VERSION "PrimaryActuatorCAN"

NS_ :

BS_:

BU_: ACM CGM EPAS_P ESP IBM OCS RCM SAS TestTool VDM Vector_XXX

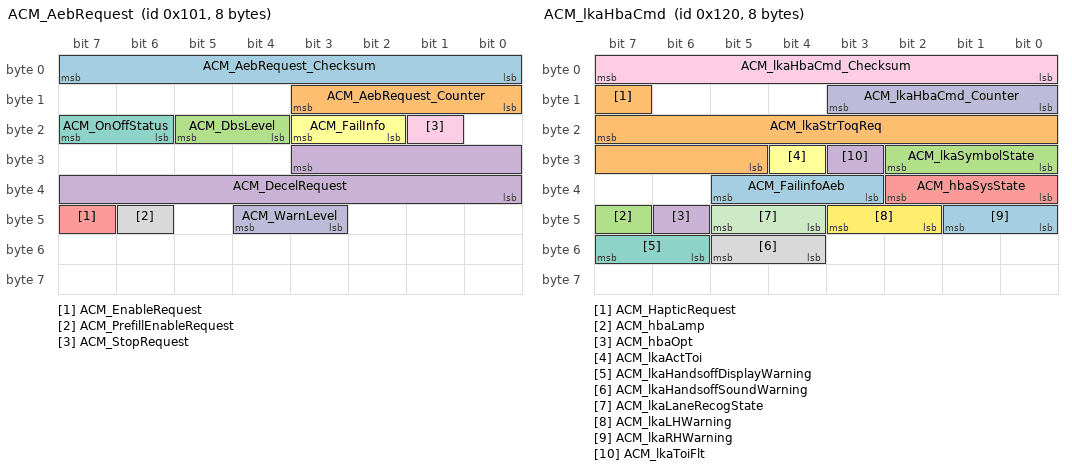
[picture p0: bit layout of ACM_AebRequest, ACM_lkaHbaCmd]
BO_ 257 ACM_AebRequest: 8 ACM
 SG_ ACM_AebRequest_Checksum : 7|8@0+ (1,0) [0|255] ""  ESP,VDM
 SG_ ACM_AebRequest_Counter : 11|4@0+ (1,0) [0|15] ""  ESP,VDM
 SG_ ACM_DbsLevel : 21|2@0+ (1,0) [0|3] ""  ESP,VDM
 SG_ ACM_DecelRequest : 27|12@0+ (0.004885,0) [0|15.998375] "m/s^2"  ESP,VDM
 SG_ ACM_EnableRequest : 47|1@0+ (1,0) [0|1] ""  ESP,VDM
 SG_ ACM_FailInfo : 19|2@0+ (1,0) [0|3] ""  ESP,VDM
 SG_ ACM_OnOffStatus : 23|2@0+ (1,0) [0|3] ""  ESP,VDM
 SG_ ACM_PrefillEnableRequest : 46|1@0+ (1,0) [0|1] ""  ESP,VDM
 SG_ ACM_StopRequest : 17|1@0+ (1,0) [0|1] ""  ESP,VDM
 SG_ ACM_WarnLevel : 44|2@0+ (1,0) [0|3] ""  ESP,VDM

BO_ 288 ACM_lkaHbaCmd: 8 ACM
 SG_ ACM_FailinfoAeb : 37|3@0+ (1,0) [0|7] ""  EPAS_P
 SG_ ACM_HapticRequest : 15|1@0+ (1,0) [0|1] ""  EPAS_P
 SG_ ACM_hbaLamp : 47|1@0+ (1,0) [0|1] ""  EPAS_P
 SG_ ACM_hbaOpt : 46|1@0+ (1,0) [0|1] ""  EPAS_P
 SG_ ACM_hbaSysState : 34|3@0+ (1,0) [0|7] ""  EPAS_P
 SG_ ACM_lkaActToi : 28|1@0+ (1,0) [0|1] ""  EPAS_P
 SG_ ACM_lkaHandsoffDisplayWarning : 55|2@0+ (1,0) [0|3] ""  EPAS_P
 SG_ ACM_lkaHandsoffSoundWarning : 53|2@0+ (1,0) [0|3] ""  EPAS_P
 SG_ ACM_lkaHbaCmd_Checksum : 7|8@0+ (1,0) [0|0] ""  EPAS_P
 SG_ ACM_lkaHbaCmd_Counter : 11|4@0+ (1,0) [0|0] ""  EPAS_P
 SG_ ACM_lkaLaneRecogState : 45|2@0+ (1,0) [0|3] ""  EPAS_P
 SG_ ACM_lkaLHWarning : 43|2@0+ (1,0) [0|3] ""  EPAS_P
 SG_ ACM_lkaRHWarning : 41|2@0+ (1,0) [0|3] ""  EPAS_P
 SG_ ACM_lkaStrToqReq : 23|11@0+ (0.0078125,-8) [-8|7.9921875] "Nm"  EPAS_P
 SG_ ACM_lkaSymbolState : 26|3@0+ (1,0) [0|7] ""  EPAS_P
 SG_ ACM_lkaToiFlt : 27|1@0+ (1,0) [0|1] ""  EPAS_P

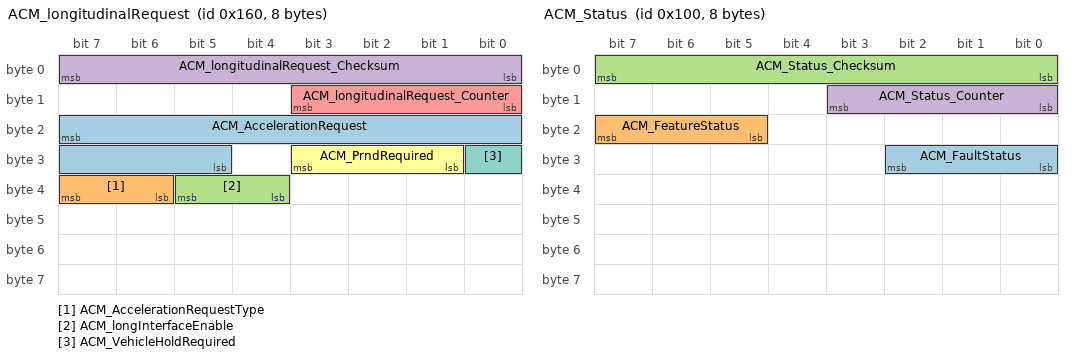
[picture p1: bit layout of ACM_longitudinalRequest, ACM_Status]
BO_ 352 ACM_longitudinalRequest: 8 ACM
 SG_ ACM_AccelerationRequest : 23|11@0+ (0.01,-10.24) [-10.24|10.23] "m/s^2"  VDM
 SG_ ACM_AccelerationRequestType : 39|2@0+ (1,0) [0|3] ""  VDM
 SG_ ACM_longInterfaceEnable : 37|2@0+ (1,0) [0|3] ""  VDM
 SG_ ACM_longitudinalRequest_Checksum : 7|8@0+ (1,0) [0|255] "-"  VDM
 SG_ ACM_longitudinalRequest_Counter : 11|4@0+ (1,0) [0|15] "-"  VDM
 SG_ ACM_PrndRequired : 27|3@0+ (1,0) [0|7] ""  VDM
 SG_ ACM_VehicleHoldRequired : 24|1@0+ (1,0) [0|1] ""  VDM

BO_ 256 ACM_Status: 8 ACM
 SG_ ACM_FaultStatus : 26|3@0+ (1,0) [0|7] ""  EPAS_P,VDM
 SG_ ACM_FeatureStatus : 23|3@0+ (1,0) [0|7] ""  EPAS_P,VDM
 SG_ ACM_Status_Checksum : 7|8@0+ (1,0) [0|255] "-"  EPAS_P,VDM
 SG_ ACM_Status_Counter : 11|4@0+ (1,0) [0|15] "-"  EPAS_P,VDM

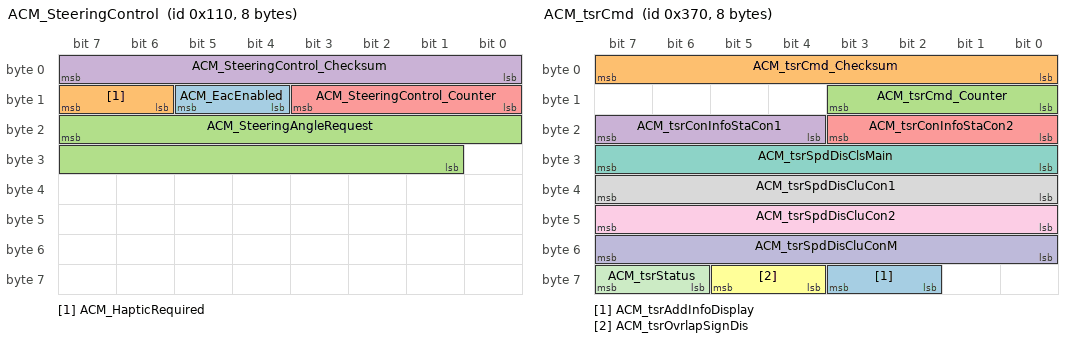
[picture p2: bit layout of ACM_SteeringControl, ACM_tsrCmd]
BO_ 272 ACM_SteeringControl: 8 ACM
 SG_ ACM_EacEnabled : 13|2@0+ (1,0) [0|3] ""  EPAS_P
 SG_ ACM_HapticRequired : 15|2@0+ (1,0) [0|3] ""  EPAS_P
 SG_ ACM_SteeringAngleRequest : 23|15@0+ (0.1,-1638.4) [-1638.4|1638.3] "deg"  EPAS_P
 SG_ ACM_SteeringControl_Checksum : 7|8@0+ (1,0) [0|0] ""  EPAS_P
 SG_ ACM_SteeringControl_Counter : 11|4@0+ (1,0) [0|0] ""  EPAS_P

BO_ 880 ACM_tsrCmd: 8 ACM
 SG_ ACM_tsrAddInfoDisplay : 59|2@0+ (1,0) [0|3] ""  Vector_XXX
 SG_ ACM_tsrCmd_Checksum : 7|8@0+ (1,0) [0|0] ""  Vector_XXX
 SG_ ACM_tsrCmd_Counter : 11|4@0+ (1,0) [0|15] ""  Vector_XXX
 SG_ ACM_tsrConInfoStaCon1 : 23|4@0+ (1,0) [0|15] ""  Vector_XXX
 SG_ ACM_tsrConInfoStaCon2 : 19|4@0+ (1,0) [0|15] ""  Vector_XXX
 SG_ ACM_tsrOvrlapSignDis : 61|2@0+ (1,0) [0|3] ""  Vector_XXX
 SG_ ACM_tsrSpdDisClsMain : 31|8@0+ (1,0) [0|255] ""  Vector_XXX
 SG_ ACM_tsrSpdDisCluCon1 : 39|8@0+ (1,0) [0|255] ""  Vector_XXX
 SG_ ACM_tsrSpdDisCluCon2 : 47|8@0+ (1,0) [0|255] ""  Vector_XXX
 SG_ ACM_tsrSpdDisCluConM : 55|8@0+ (1,0) [0|255] ""  Vector_XXX
 SG_ ACM_tsrStatus : 63|2@0+ (1,0) [0|3] ""  Vector_XXX

BO_ 789 BCM_Status: 2 VDM
 SG_ BCM_AmbientAirTemperature : 15|8@0- (1,0) [-60|100] "degC"  ESP

BO_ 1800 Diag_PhysReq_ACM_PrimaryActuator: 8 TestTool

BO_ 1843 Diag_PhysReq_EPAS_P_PrimaryActua: 8 TestTool

BO_ 1845 Diag_PhysReq_ESP_PrimaryActuator: 8 TestTool

BO_ 1846 Diag_PhysReq_IBM_PrimaryActuator: 8 TestTool

BO_ 1844 Diag_PhysReq_RCM_PrimaryActuator: 8 TestTool

BO_ 1864 Diag_PhysResp_ACM_PrimaryActuato: 8 ACM

BO_ 1907 Diag_PhysResp_EPAS_P_PrimaryActu: 8 EPAS_P

BO_ 1909 Diag_PhysResp_ESP_PrimaryActuato: 8 ESP

BO_ 1910 Diag_PhysResp_IBM_PrimaryActuato: 8 IBM

BO_ 1908 Diag_PhysResp_RCM_PrimaryActuato: 8 RCM

BO_ 1328 Dummy_ACM_PrimaryActuatorCAN: 1 ACM
 SG_ Dummy_ACM_PrimaryActuatorCAN : 7|8@0+ (1,0) [0|255] ""  TestTool

BO_ 1329 Dummy_CGM_PrimaryActuatorCAN: 1 CGM
 SG_ Dummy_CGM_PrimaryActuatorCAN : 7|8@0+ (1,0) [0|255] ""  TestTool

BO_ 1330 Dummy_VDM_PrimaryActuatorCAN: 1 VDM
 SG_ Dummy_VDM_PrimaryActuatorCAN : 7|8@0+ (1,0) [0|255] ""  TestTool

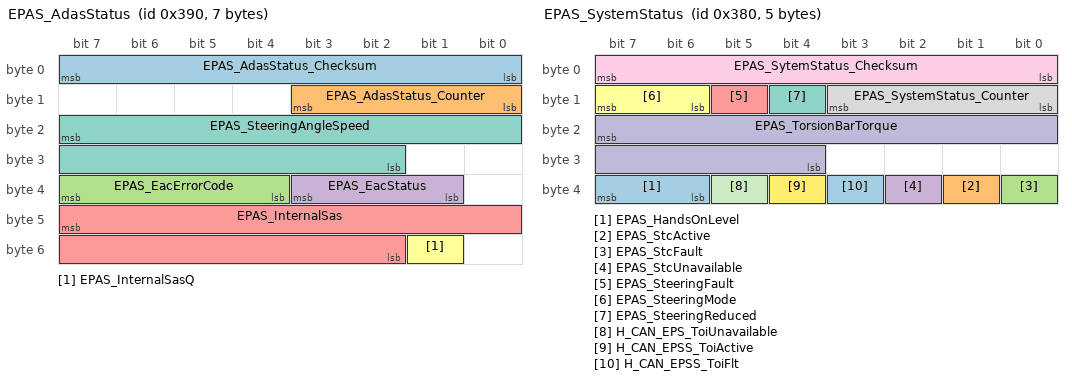
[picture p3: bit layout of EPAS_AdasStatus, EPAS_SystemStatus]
BO_ 912 EPAS_AdasStatus: 7 EPAS_P
 SG_ EPAS_AdasStatus_Checksum : 7|8@0+ (1,0) [0|0] ""  ACM,VDM
 SG_ EPAS_AdasStatus_Counter : 11|4@0+ (1,0) [0|15] ""  ACM,VDM
 SG_ EPAS_EacErrorCode : 39|4@0+ (1,0) [0|15] ""  ACM,VDM
 SG_ EPAS_EacStatus : 35|3@0+ (1,0) [0|7] ""  ACM,VDM
 SG_ EPAS_InternalSas : 47|14@0+ (0.1,-819.2) [-819.2|819] "deg"  ACM,VDM
 SG_ EPAS_InternalSasQ : 49|1@0+ (1,0) [0|1] ""  ACM,VDM
 SG_ EPAS_SteeringAngleSpeed : 23|14@0+ (0.1,-819) [-819|819.3] "deg/s"  ACM,VDM

BO_ 896 EPAS_SystemStatus: 5 EPAS_P
 SG_ EPAS_HandsOnLevel : 39|2@0+ (1,0) [0|3] ""  ACM,VDM
 SG_ EPAS_StcActive : 33|1@0+ (1,0) [0|1] ""  ACM,VDM
 SG_ EPAS_StcFault : 32|1@0+ (1,0) [0|1] ""  ACM,VDM
 SG_ EPAS_StcUnavailable : 34|1@0+ (1,0) [0|1] ""  ACM,VDM
 SG_ EPAS_SteeringFault : 13|1@0+ (1,0) [0|1] ""  ACM,VDM
 SG_ EPAS_SteeringMode : 15|2@0+ (1,0) [0|3] ""  ACM,VDM
 SG_ EPAS_SteeringReduced : 12|1@0+ (1,0) [0|1] ""  ACM,VDM
 SG_ EPAS_SystemStatus_Counter : 11|4@0+ (1,0) [0|15] ""  ACM,VDM
 SG_ EPAS_SytemStatus_Checksum : 7|8@0+ (1,0) [0|255] ""  ACM,VDM
 SG_ EPAS_TorsionBarTorque : 23|12@0+ (0.01,-20.5) [-20.49|20.43] ""  ACM,VDM
 SG_ H_CAN_EPS_ToiUnavailable : 37|1@0+ (1,0) [0|1] ""  ACM,VDM
 SG_ H_CAN_EPSS_ToiActive : 36|1@0+ (1,0) [0|1] ""  ACM,VDM
 SG_ H_CAN_EPSS_ToiFlt : 35|1@0+ (1,0) [0|1] ""  ACM,VDM

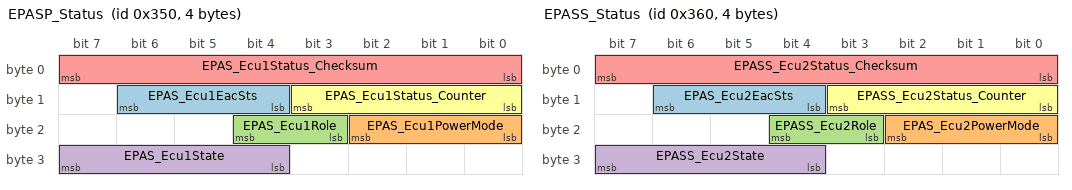
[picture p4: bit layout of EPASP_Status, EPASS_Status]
BO_ 848 EPASP_Status: 4 EPAS_P
 SG_ EPAS_Ecu1EacSts : 14|3@0+ (1,0) [0|7] ""  ACM,VDM
 SG_ EPAS_Ecu1PowerMode : 18|3@0+ (1,0) [0|7] ""  ACM,VDM
 SG_ EPAS_Ecu1Role : 20|2@0+ (1,0) [0|3] ""  ACM,VDM
 SG_ EPAS_Ecu1State : 31|4@0+ (1,0) [0|15] ""  ACM,VDM
 SG_ EPAS_Ecu1Status_Checksum : 7|8@0+ (1,0) [0|255] ""  ACM,VDM
 SG_ EPAS_Ecu1Status_Counter : 11|4@0+ (1,0) [0|15] ""  ACM,VDM

BO_ 864 EPASS_Status: 4 VDM
 SG_ EPAS_Ecu2EacSts : 14|3@0+ (1,0) [0|7] ""  ACM,EPAS_P
 SG_ EPAS_Ecu2PowerMode : 18|3@0+ (1,0) [0|7] ""  ACM,EPAS_P
 SG_ EPASS_Ecu2Role : 20|2@0+ (1,0) [0|3] ""  ACM,EPAS_P
 SG_ EPASS_Ecu2State : 31|4@0+ (1,0) [0|15] ""  ACM,EPAS_P
 SG_ EPASS_Ecu2Status_Checksum : 7|8@0+ (1,0) [0|255] ""  ACM,EPAS_P
 SG_ EPASS_Ecu2Status_Counter : 11|4@0+ (1,0) [0|15] ""  ACM,EPAS_P

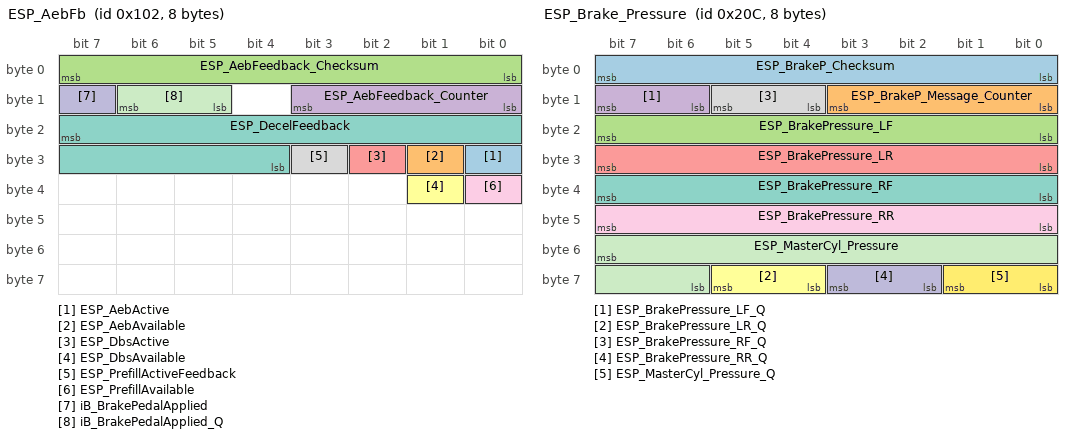
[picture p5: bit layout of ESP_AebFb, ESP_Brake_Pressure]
BO_ 258 ESP_AebFb: 8 ESP
 SG_ ESP_AebActive : 24|1@0+ (1,0) [0|1] ""  ACM
 SG_ ESP_AebAvailable : 25|1@0+ (1,0) [0|1] ""  ACM
 SG_ ESP_AebFeedback_Checksum : 7|8@0+ (1,0) [0|255] ""  ACM
 SG_ ESP_AebFeedback_Counter : 11|4@0+ (1,0) [0|15] ""  ACM
 SG_ ESP_DbsActive : 26|1@0+ (1,0) [0|1] ""  ACM
 SG_ ESP_DbsAvailable : 33|1@0+ (1,0) [0|1] ""  ACM
 SG_ ESP_DecelFeedback : 23|12@0+ (0.004885,-16) [-16|3.99919] "m/s^2"  ACM
 SG_ ESP_PrefillActiveFeedback : 27|1@0+ (1,0) [0|1] ""  ACM
 SG_ ESP_PrefillAvailable : 32|1@0+ (1,0) [0|1] ""  ACM
 SG_ iB_BrakePedalApplied : 15|1@0+ (1,0) [0|1] ""  ACM
 SG_ iB_BrakePedalApplied_Q : 14|2@0+ (1,0) [0|3] ""  ACM

BO_ 524 ESP_Brake_Pressure: 8 ESP
 SG_ ESP_BrakeP_Checksum : 7|8@0+ (1,0) [0|255] ""  ACM,RCM,VDM
 SG_ ESP_BrakeP_Message_Counter : 11|4@0+ (1,0) [0|15] ""  ACM,RCM,VDM
 SG_ ESP_BrakePressure_LF : 23|8@0+ (1,0) [0|255] "bar"  ACM,RCM,VDM
 SG_ ESP_BrakePressure_LF_Q : 15|2@0+ (1,0) [0|3] ""  ACM,RCM,VDM
 SG_ ESP_BrakePressure_LR : 31|8@0+ (1,0) [0|255] "bar"  ACM,RCM,VDM
 SG_ ESP_BrakePressure_LR_Q : 61|2@0+ (1,0) [0|3] ""  ACM,RCM,VDM
 SG_ ESP_BrakePressure_RF : 39|8@0+ (1,0) [0|255] "bar"  ACM,RCM,VDM
 SG_ ESP_BrakePressure_RF_Q : 13|2@0+ (1,0) [0|3] ""  ACM,RCM,VDM
 SG_ ESP_BrakePressure_RR : 47|8@0+ (1,0) [0|255] "bar"  ACM,RCM,VDM
 SG_ ESP_BrakePressure_RR_Q : 59|2@0+ (1,0) [0|3] ""  ACM,RCM,VDM
 SG_ ESP_MasterCyl_Pressure : 55|10@0+ (0.25,0) [0|255] "bar"  ACM,RCM,VDM
 SG_ ESP_MasterCyl_Pressure_Q : 57|2@0+ (1,0) [0|3] ""  ACM,RCM,VDM

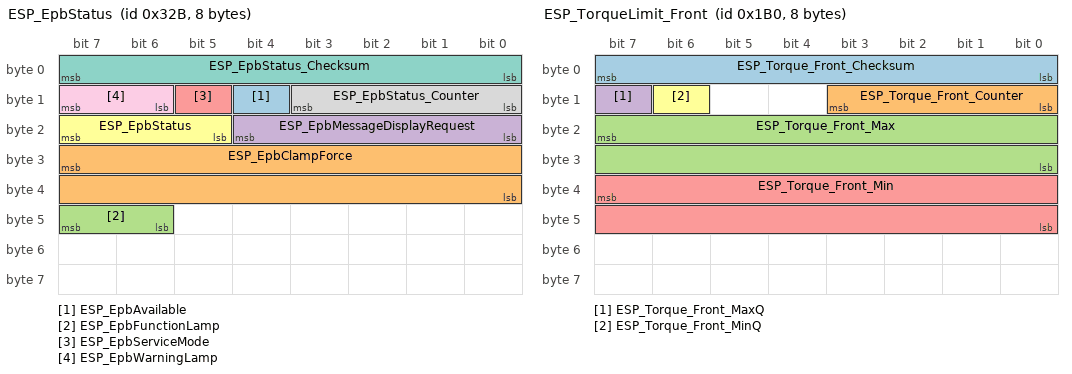
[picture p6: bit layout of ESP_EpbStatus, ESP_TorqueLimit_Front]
BO_ 811 ESP_EpbStatus: 8 ESP
 SG_ ESP_EpbAvailable : 12|1@0+ (1,0) [0|1] ""  ACM,VDM
 SG_ ESP_EpbClampForce : 31|16@0+ (1,0) [0|65534] "N"  ACM,VDM
 SG_ ESP_EpbFunctionLamp : 47|2@0+ (1,0) [0|3] ""  ACM,VDM
 SG_ ESP_EpbMessageDisplayRequest : 20|5@0+ (1,0) [0|30] ""  ACM,VDM
 SG_ ESP_EpbServiceMode : 13|1@0+ (1,0) [0|1] ""  ACM,VDM
 SG_ ESP_EpbStatus : 23|3@0+ (1,0) [0|7] ""  ACM,VDM
 SG_ ESP_EpbStatus_Checksum : 7|8@0+ (1,0) [0|255] ""  ACM,VDM
 SG_ ESP_EpbStatus_Counter : 11|4@0+ (1,0) [0|15] ""  ACM,VDM
 SG_ ESP_EpbWarningLamp : 15|2@0+ (1,0) [0|3] ""  ACM,VDM

BO_ 520 ESP_Status: 8 ESP
 SG_ ESP_Abs_Active : 23|1@0+ (1,0) [0|1] ""  ACM,CGM,EPAS_P,RCM,VDM
 SG_ ESP_Abs_OffRoad_Mode : 16|1@0+ (1,0) [0|1] ""  ACM,CGM,EPAS_P,RCM,VDM
 SG_ ESP_BrakeLightActive : 13|1@0+ (1,0) [0|1] ""  ACM,CGM,EPAS_P,RCM,VDM
 SG_ ESP_BrakeLightActive_Q : 12|1@0+ (1,0) [0|1] ""  ACM,CGM,EPAS_P,RCM,VDM
 SG_ ESP_BrkTrq : 38|15@0+ (2,-65534) [-65534|0] "Nm"  ACM,CGM,EPAS_P,RCM,VDM
 SG_ ESP_Dtc_Active : 26|1@0+ (1,0) [0|1] "Enum"  ACM,CGM,EPAS_P,RCM,VDM
 SG_ ESP_Esp_Active : 21|1@0+ (1,0) [0|1] ""  ACM,CGM,EPAS_P,RCM,VDM
 SG_ ESP_FaultLamp_ABS : 20|1@0+ (1,0) [0|1] ""  ACM,CGM,EPAS_P,RCM,VDM
 SG_ ESP_FaultLamp_EBD : 18|1@0+ (1,0) [0|1] ""  ACM,CGM,EPAS_P,RCM,VDM
 SG_ ESP_FaultLamp_VDC : 19|1@0+ (1,0) [0|1] ""  ACM,CGM,EPAS_P,RCM,VDM
 SG_ ESP_Hba_Active : 31|1@0+ (1,0) [0|1] ""  ACM,CGM,EPAS_P,RCM,VDM
 SG_ ESP_Hhc_Active : 14|1@0+ (1,0) [0|1] ""  ACM,CGM,EPAS_P,RCM,VDM
 SG_ ESP_Hhc_Available : 15|1@0+ (1,0) [0|1] ""  ACM,CGM,EPAS_P,RCM,VDM
 SG_ ESP_Lfc_Active : 39|1@0+ (1,0) [0|1] ""  ACM,CGM,EPAS_P,RCM,VDM
 SG_ ESP_Lfc_Available : 30|1@0+ (1,0) [0|1] ""  ACM,CGM,EPAS_P,RCM,VDM
 SG_ ESP_Partial_Mode : 25|2@0+ (1,0) [0|3] ""  ACM,CGM,EPAS_P,RCM,VDM
 SG_ ESP_Status_Checksum : 7|8@0+ (1,0) [0|255] ""  ACM,CGM,EPAS_P,RCM,VDM
 SG_ ESP_Status_Counter : 11|4@0+ (1,0) [0|15] ""  ACM,CGM,EPAS_P,RCM,VDM
 SG_ ESP_Tsm_Active : 17|1@0+ (1,0) [0|1] ""  ACM,CGM,EPAS_P,RCM,VDM
 SG_ ESP_Vehicle_Speed : 55|16@0+ (0.01,0) [0|400] "kph"  ACM,CGM,EPAS_P,RCM,VDM
 SG_ ESP_Vehicle_Speed_Q : 28|2@0+ (1,0) [0|3] ""  ACM,CGM,EPAS_P,RCM,VDM

BO_ 432 ESP_TorqueLimit_Front: 8 ESP
 SG_ ESP_Torque_Front_Checksum : 7|8@0+ (1,0) [0|255] ""  VDM
 SG_ ESP_Torque_Front_Counter : 11|4@0+ (1,0) [0|15] ""  VDM
 SG_ ESP_Torque_Front_Max : 23|16@0+ (0.5,-16384) [-16384|16383] "Nm"  VDM
 SG_ ESP_Torque_Front_MaxQ : 15|1@0+ (1,0) [0|1] ""  VDM
 SG_ ESP_Torque_Front_Min : 39|16@0+ (0.5,-16384) [-16384|16383] "Nm"  VDM
 SG_ ESP_Torque_Front_MinQ : 14|1@0+ (1,0) [0|1] ""  VDM

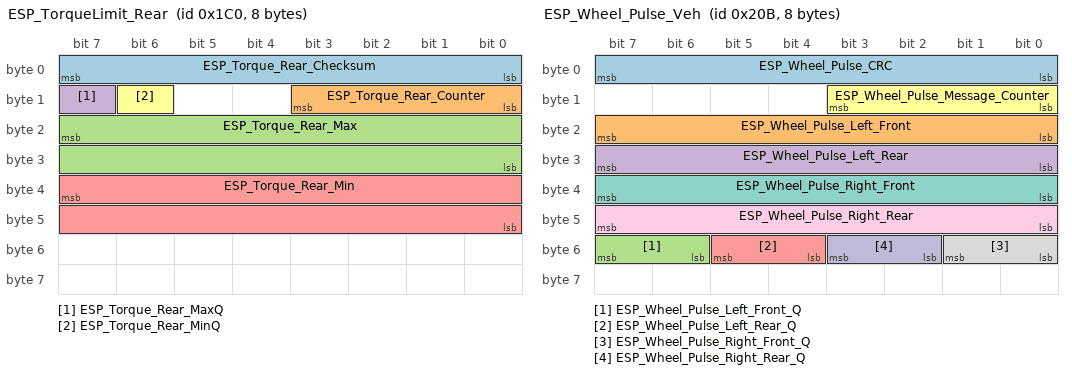
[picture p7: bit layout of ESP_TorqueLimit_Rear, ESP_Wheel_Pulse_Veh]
BO_ 448 ESP_TorqueLimit_Rear: 8 ESP
 SG_ ESP_Torque_Rear_Checksum : 7|8@0+ (1,0) [0|255] ""  VDM
 SG_ ESP_Torque_Rear_Counter : 11|4@0+ (1,0) [0|15] ""  VDM
 SG_ ESP_Torque_Rear_Max : 23|16@0+ (0.5,-16384) [-16384|16383] "Nm"  VDM
 SG_ ESP_Torque_Rear_MaxQ : 15|1@0+ (1,0) [0|1] ""  VDM
 SG_ ESP_Torque_Rear_Min : 39|16@0+ (0.5,-16384) [-16384|16383] "Nm"  VDM
 SG_ ESP_Torque_Rear_MinQ : 14|1@0+ (1,0) [0|1] ""  VDM

BO_ 523 ESP_Wheel_Pulse_Veh: 8 ESP
 SG_ ESP_Wheel_Pulse_CRC : 7|8@0+ (1,0) [0|255] ""  ACM,VDM
 SG_ ESP_Wheel_Pulse_Left_Front : 23|8@0+ (1,0) [0|255] "Pulse"  ACM,VDM
 SG_ ESP_Wheel_Pulse_Left_Front_Q : 55|2@0+ (1,0) [0|3] ""  ACM,VDM
 SG_ ESP_Wheel_Pulse_Left_Rear : 31|8@0+ (1,0) [0|255] "Pulse"  ACM,VDM
 SG_ ESP_Wheel_Pulse_Left_Rear_Q : 53|2@0+ (1,0) [0|3] ""  ACM,VDM
 SG_ ESP_Wheel_Pulse_Message_Counter : 11|4@0+ (1,0) [0|15] ""  ACM,VDM
 SG_ ESP_Wheel_Pulse_Right_Front : 39|8@0+ (1,0) [0|255] "Pulse"  ACM,VDM
 SG_ ESP_Wheel_Pulse_Right_Front_Q : 49|2@0+ (1,0) [0|3] ""  ACM,VDM
 SG_ ESP_Wheel_Pulse_Right_Rear : 47|8@0+ (1,0) [0|255] "Pulse"  ACM,VDM
 SG_ ESP_Wheel_Pulse_Right_Rear_Q : 51|2@0+ (1,0) [0|3] ""  ACM,VDM

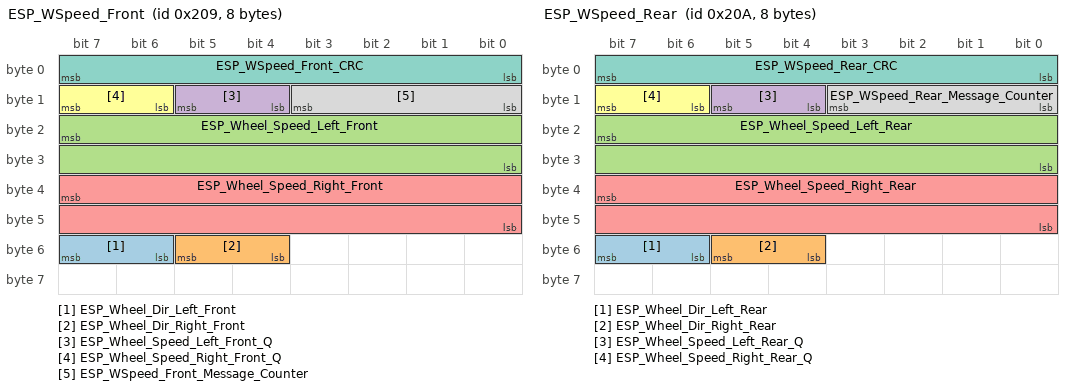
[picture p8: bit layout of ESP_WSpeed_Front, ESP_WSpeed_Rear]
BO_ 521 ESP_WSpeed_Front: 8 ESP
 SG_ ESP_Wheel_Dir_Left_Front : 55|2@0+ (1,0) [0|3] ""  ACM,VDM
 SG_ ESP_Wheel_Dir_Right_Front : 53|2@0+ (1,0) [0|3] ""  ACM,VDM
 SG_ ESP_Wheel_Speed_Left_Front : 23|16@0+ (0.01,0) [0|400] "kph"  ACM,VDM
 SG_ ESP_Wheel_Speed_Left_Front_Q : 13|2@0+ (1,0) [0|3] ""  ACM,VDM
 SG_ ESP_Wheel_Speed_Right_Front : 39|16@0+ (0.01,0) [0|400] "kph"  ACM,VDM
 SG_ ESP_Wheel_Speed_Right_Front_Q : 15|2@0+ (1,0) [0|3] ""  ACM,VDM
 SG_ ESP_WSpeed_Front_CRC : 7|8@0+ (1,0) [0|255] ""  ACM,VDM
 SG_ ESP_WSpeed_Front_Message_Counter : 11|4@0+ (1,0) [0|15] ""  ACM,VDM

BO_ 522 ESP_WSpeed_Rear: 8 ESP
 SG_ ESP_Wheel_Dir_Left_Rear : 55|2@0+ (1,0) [0|3] ""  ACM,VDM
 SG_ ESP_Wheel_Dir_Right_Rear : 53|2@0+ (1,0) [0|3] ""  ACM,VDM
 SG_ ESP_Wheel_Speed_Left_Rear : 23|16@0+ (0.01,0) [0|400] "kph"  ACM,VDM
 SG_ ESP_Wheel_Speed_Left_Rear_Q : 13|2@0+ (1,0) [0|3] ""  ACM,VDM
 SG_ ESP_Wheel_Speed_Right_Rear : 39|16@0+ (0.01,0) [0|400] "kph"  ACM,VDM
 SG_ ESP_Wheel_Speed_Right_Rear_Q : 15|2@0+ (1,0) [0|3] ""  ACM,VDM
 SG_ ESP_WSpeed_Rear_CRC : 7|8@0+ (1,0) [0|255] ""  ACM,VDM
 SG_ ESP_WSpeed_Rear_Message_Counter : 11|4@0+ (1,0) [0|15] ""  ACM,VDM

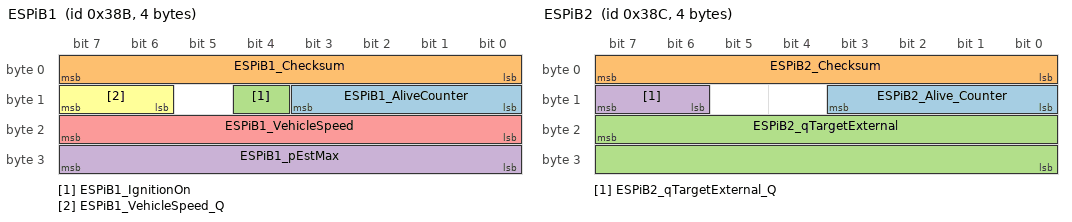
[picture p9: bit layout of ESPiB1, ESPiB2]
BO_ 907 ESPiB1: 4 ESP
 SG_ ESPiB1_AliveCounter : 11|4@0+ (1,0) [0|15] ""  IBM
 SG_ ESPiB1_Checksum : 7|8@0+ (1,0) [0|255] ""  IBM
 SG_ ESPiB1_IgnitionOn : 12|1@0+ (1,0) [0|1] ""  IBM
 SG_ ESPiB1_pEstMax : 31|8@0+ (1,0) [0|250] "bar"  IBM
 SG_ ESPiB1_VehicleSpeed : 23|8@0+ (0.4,0) [0|100] "m/s"  IBM
 SG_ ESPiB1_VehicleSpeed_Q : 15|2@0+ (1,0) [0|3] ""  IBM

BO_ 908 ESPiB2: 4 ESP
 SG_ ESPiB2_Alive_Counter : 11|4@0+ (1,0) [0|15] ""  IBM
 SG_ ESPiB2_Checksum : 7|8@0+ (1,0) [0|255] ""  IBM
 SG_ ESPiB2_qTargetExternal : 23|16@0+ (0.0078125,-252) [-252|252] "ml/s"  IBM
 SG_ ESPiB2_qTargetExternal_Q : 15|2@0+ (1,0) [0|3] ""  IBM

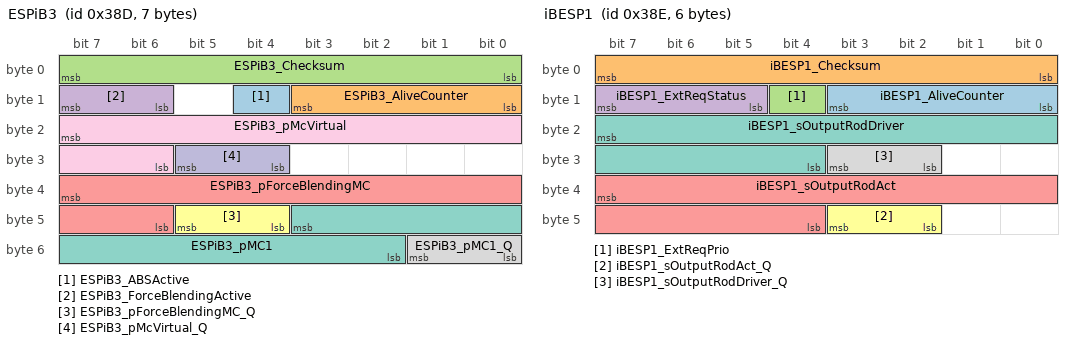
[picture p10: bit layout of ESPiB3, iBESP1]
BO_ 909 ESPiB3: 7 ESP
 SG_ ESPiB3_ABSActive : 12|1@0+ (1,0) [0|1] ""  IBM
 SG_ ESPiB3_AliveCounter : 11|4@0+ (1,0) [0|15] ""  IBM
 SG_ ESPiB3_Checksum : 7|8@0+ (1,0) [0|255] ""  IBM
 SG_ ESPiB3_ForceBlendingActive : 15|2@0+ (1,0) [0|3] ""  IBM
 SG_ ESPiB3_pForceBlendingMC : 39|10@0+ (0.25,0) [0|250] ""  IBM
 SG_ ESPiB3_pForceBlendingMC_Q : 45|2@0+ (1,0) [0|3] ""  IBM
 SG_ ESPiB3_pMC1 : 43|10@0+ (0.3,-30) [-30|276.6] "bar"  IBM
 SG_ ESPiB3_pMC1_Q : 49|2@0+ (1,0) [0|3] ""  IBM
 SG_ ESPiB3_pMcVirtual : 23|10@0+ (0.25,0) [0|250] "bar"  IBM
 SG_ ESPiB3_pMcVirtual_Q : 29|2@0+ (1,0) [0|3] ""  IBM

BO_ 910 iBESP1: 6 IBM
 SG_ iBESP1_AliveCounter : 11|4@0+ (1,0) [0|15] ""  ESP,VDM
 SG_ iBESP1_Checksum : 7|8@0+ (1,0) [0|255] ""  ESP,VDM
 SG_ iBESP1_ExtReqPrio : 12|1@0+ (1,0) [0|1] ""  ESP,VDM
 SG_ iBESP1_ExtReqStatus : 15|3@0+ (1,0) [0|7] ""  ESP,VDM
 SG_ iBESP1_sOutputRodAct : 39|12@0+ (0.015625,-5) [-5|47] "mm"  ESP,VDM
 SG_ iBESP1_sOutputRodAct_Q : 43|2@0+ (1,0) [0|3] ""  ESP,VDM
 SG_ iBESP1_sOutputRodDriver : 23|12@0+ (0.015625,-5) [-5|47] "mm"  ESP,VDM
 SG_ iBESP1_sOutputRodDriver_Q : 27|2@0+ (1,0) [0|3] ""  ESP,VDM

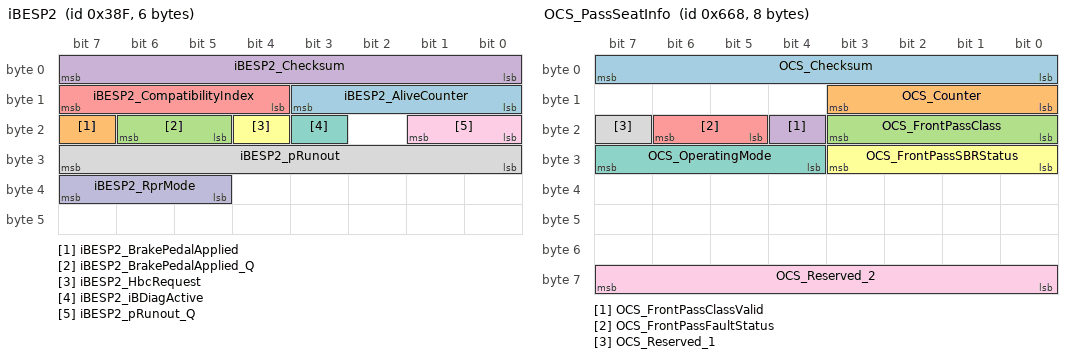
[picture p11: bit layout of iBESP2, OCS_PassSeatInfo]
BO_ 911 iBESP2: 6 IBM
 SG_ iBESP2_AliveCounter : 11|4@0+ (1,0) [0|15] ""  ACM,ESP,VDM
 SG_ iBESP2_BrakePedalApplied : 23|1@0+ (1,0) [0|1] ""  ACM,ESP,VDM
 SG_ iBESP2_BrakePedalApplied_Q : 22|2@0+ (1,0) [0|3] ""  ACM,ESP,VDM
 SG_ iBESP2_Checksum : 7|8@0+ (1,0) [0|255] ""  ACM,ESP,VDM
 SG_ iBESP2_CompatibilityIndex : 15|4@0+ (1,0) [0|15] ""  ACM,ESP,VDM
 SG_ iBESP2_HbcRequest : 20|1@0+ (1,0) [0|1] ""  ACM,ESP,VDM
 SG_ iBESP2_iBDiagActive : 19|1@0+ (1,0) [0|1] ""  ACM,ESP,VDM
 SG_ iBESP2_pRunout : 31|8@0+ (1,0) [0|250] "bar"  ACM,ESP,VDM
 SG_ iBESP2_pRunout_Q : 17|2@0+ (1,0) [0|3] ""  ACM,ESP,VDM
 SG_ iBESP2_RprMode : 39|3@0+ (1,0) [0|7] ""  ACM,ESP,VDM

BO_ 1640 OCS_PassSeatInfo: 8 OCS
 SG_ OCS_Checksum : 0|8@1+ (1,0) [0|255] "-"  RCM
 SG_ OCS_Counter : 8|4@1+ (1,0) [0|15] "-"  RCM
 SG_ OCS_FrontPassClass : 16|4@1+ (1,0) [0|15] ""  RCM
 SG_ OCS_FrontPassClassValid : 20|1@1+ (1,0) [0|1] ""  RCM
 SG_ OCS_FrontPassFaultStatus : 21|2@1+ (1,0) [0|3] ""  RCM
 SG_ OCS_FrontPassSBRStatus : 24|4@1+ (1,0) [0|15] ""  RCM
 SG_ OCS_OperatingMode : 28|4@1+ (1,0) [0|15] ""  RCM
 SG_ OCS_Reserved_1 : 23|1@1+ (1,0) [0|1] ""  RCM
 SG_ OCS_Reserved_2 : 56|8@1+ (1,0) [0|255] ""  RCM

BO_ 516 RCM_ALR_Status: 1 RCM
 SG_ RCM_ALR_Status_Signal : 0|2@1+ (1,0) [0|3] ""  OCS

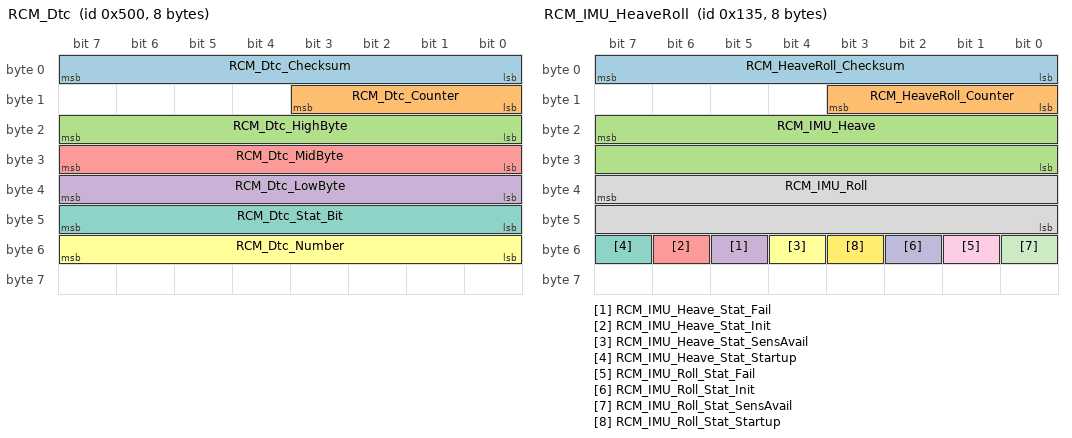
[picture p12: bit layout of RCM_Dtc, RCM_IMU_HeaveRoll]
BO_ 1280 RCM_Dtc: 8 RCM
 SG_ RCM_Dtc_Checksum : 7|8@0+ (1,0) [0|25] ""  VDM
 SG_ RCM_Dtc_Counter : 11|4@0+ (1,0) [0|15] ""  VDM
 SG_ RCM_Dtc_HighByte : 23|8@0+ (1,0) [0|255] ""  VDM
 SG_ RCM_Dtc_LowByte : 39|8@0+ (1,0) [0|255] ""  VDM
 SG_ RCM_Dtc_MidByte : 31|8@0+ (1,0) [0|255] ""  VDM
 SG_ RCM_Dtc_Number : 55|8@0+ (1,0) [0|255] ""  VDM
 SG_ RCM_Dtc_Stat_Bit : 47|8@0+ (1,0) [0|255] ""  VDM

BO_ 309 RCM_IMU_HeaveRoll: 8 RCM
 SG_ RCM_HeaveRoll_Checksum : 7|8@0+ (1,0) [0|25] ""  VDM
 SG_ RCM_HeaveRoll_Counter : 11|4@0+ (1,0) [0|15] ""  VDM
 SG_ RCM_IMU_Heave : 23|16@0+ (0.004998293,-163.784065024) [-34.32328|34.32328] "m/s2"  VDM
 SG_ RCM_IMU_Heave_Stat_Fail : 53|1@0+ (1,0) [0|1] ""  VDM
 SG_ RCM_IMU_Heave_Stat_Init : 54|1@0+ (1,0) [0|1] ""  VDM
 SG_ RCM_IMU_Heave_Stat_SensAvail : 52|1@0+ (1,0) [0|1] ""  VDM
 SG_ RCM_IMU_Heave_Stat_Startup : 55|1@0+ (1,0) [0|1] ""  VDM
 SG_ RCM_IMU_Roll : 39|16@0+ (0.0125,-409.6) [-100.0125|100.0125] "deg/sec"  VDM
 SG_ RCM_IMU_Roll_Stat_Fail : 49|1@0+ (1,0) [0|1] ""  VDM
 SG_ RCM_IMU_Roll_Stat_Init : 50|1@0+ (1,0) [0|1] ""  VDM
 SG_ RCM_IMU_Roll_Stat_SensAvail : 48|1@0+ (1,0) [0|1] ""  VDM
 SG_ RCM_IMU_Roll_Stat_Startup : 51|1@0+ (1,0) [0|1] ""  VDM

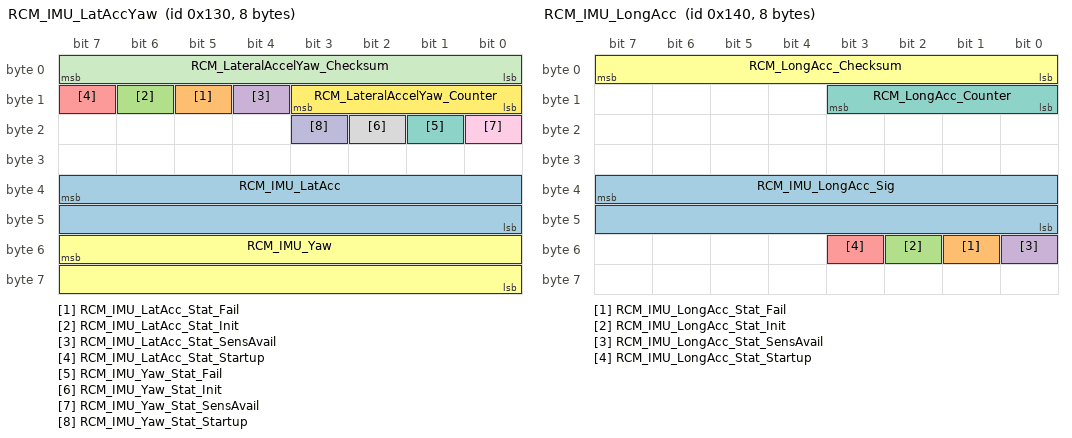
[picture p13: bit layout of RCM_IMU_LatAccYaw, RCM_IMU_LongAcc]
BO_ 304 RCM_IMU_LatAccYaw: 8 RCM
 SG_ RCM_IMU_LatAcc : 39|16@0+ (0.004998293,-163.784065024) [-40.961|40.961] "m/s2"  ACM,ESP,VDM
 SG_ RCM_IMU_LatAcc_Stat_Fail : 13|1@0+ (1,0) [0|1] ""  ACM,ESP,VDM
 SG_ RCM_IMU_LatAcc_Stat_Init : 14|1@0+ (1,0) [0|1] ""  ACM,ESP,VDM
 SG_ RCM_IMU_LatAcc_Stat_SensAvail : 12|1@0+ (1,0) [0|1] ""  ACM,ESP,VDM
 SG_ RCM_IMU_LatAcc_Stat_Startup : 15|1@0+ (1,0) [0|1] ""  ACM,ESP,VDM
 SG_ RCM_IMU_Yaw : 55|16@0+ (0.0125,-409.6) [-163.85|163.85] "deg/sec"  ACM,ESP,VDM
 SG_ RCM_IMU_Yaw_Stat_Fail : 17|1@0+ (1,0) [0|1] ""  ACM,ESP,VDM
 SG_ RCM_IMU_Yaw_Stat_Init : 18|1@0+ (1,0) [0|1] ""  ACM,ESP,VDM
 SG_ RCM_IMU_Yaw_Stat_SensAvail : 16|1@0+ (1,0) [0|1] ""  ACM,ESP,VDM
 SG_ RCM_IMU_Yaw_Stat_Startup : 19|1@0+ (1,0) [0|1] ""  ACM,ESP,VDM
 SG_ RCM_LateralAccelYaw_Checksum : 7|8@0+ (1,0) [0|25] ""  ACM,ESP,VDM
 SG_ RCM_LateralAccelYaw_Counter : 11|4@0+ (1,0) [0|15] ""  ACM,ESP,VDM

BO_ 320 RCM_IMU_LongAcc: 8 RCM
 SG_ RCM_IMU_LongAcc_Sig : 39|16@0+ (0.004998293,-163.784065024) [-40.961|40.961] "m/s2"  ACM,ESP,VDM
 SG_ RCM_IMU_LongAcc_Stat_Fail : 49|1@0+ (1,0) [0|1] ""  ACM,ESP,VDM
 SG_ RCM_IMU_LongAcc_Stat_Init : 50|1@0+ (1,0) [0|1] ""  ACM,ESP,VDM
 SG_ RCM_IMU_LongAcc_Stat_SensAvail : 48|1@0+ (1,0) [0|1] ""  ACM,ESP,VDM
 SG_ RCM_IMU_LongAcc_Stat_Startup : 51|1@0+ (1,0) [0|1] ""  ACM,ESP,VDM
 SG_ RCM_LongAcc_Checksum : 7|8@0+ (1,0) [0|25] ""  ACM,ESP,VDM
 SG_ RCM_LongAcc_Counter : 11|4@0+ (1,0) [0|15] ""  ACM,ESP,VDM

BO_ 1281 RCM_SerialIdentifier: 8 RCM
 SG_ RCM_SerialNumber : 7|64@0+ (1,0) [0|1.84467440737096E+019] ""  ESP,VDM

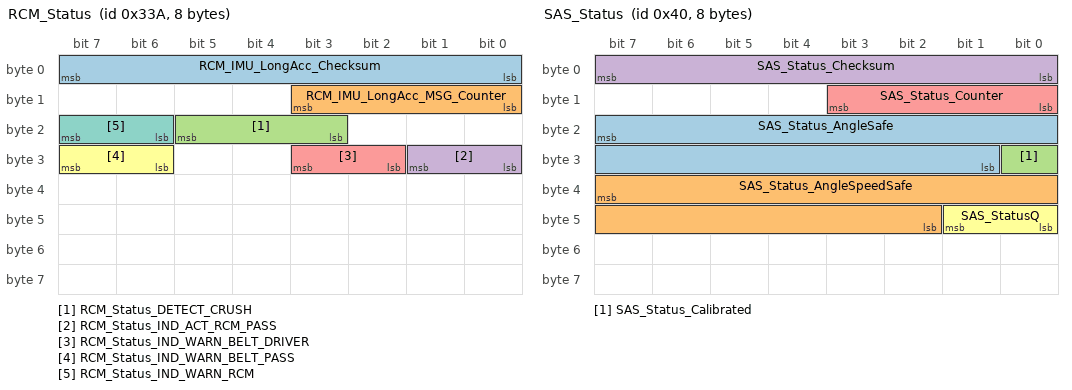
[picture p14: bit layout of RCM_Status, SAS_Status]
BO_ 826 RCM_Status: 8 RCM
 SG_ RCM_IMU_LongAcc_Checksum : 7|8@0+ (1,0) [0|25] ""  ACM,ESP,VDM
 SG_ RCM_IMU_LongAcc_MSG_Counter : 11|4@0+ (1,0) [0|15] ""  ACM,ESP,VDM
 SG_ RCM_Status_DETECT_CRUSH : 21|3@0+ (1,0) [0|7] ""  ACM,ESP,VDM
 SG_ RCM_Status_IND_ACT_RCM_PASS : 25|2@0+ (1,0) [0|3] ""  ACM,ESP,VDM
 SG_ RCM_Status_IND_WARN_BELT_DRIVER : 27|2@0+ (1,0) [0|3] ""  ACM,ESP,VDM
 SG_ RCM_Status_IND_WARN_BELT_PASS : 31|2@0+ (1,0) [0|3] ""  ACM,ESP,VDM
 SG_ RCM_Status_IND_WARN_RCM : 23|2@0+ (1,0) [0|3] ""  ACM,ESP,VDM

BO_ 64 SAS_Status: 8 SAS
 SG_ SAS_Status_AngleSafe : 23|15@0- (0.0009765625,0) [-14.5|14.5] "rad"  ACM,EPAS_P,ESP,RCM,VDM
 SG_ SAS_Status_AngleSpeedSafe : 39|14@0- (0.0078125,0) [-50|50] "rad/s"  ACM,EPAS_P,ESP,RCM,VDM
 SG_ SAS_Status_Calibrated : 24|1@0+ (1,0) [0|1] ""  ACM,EPAS_P,ESP,RCM,VDM
 SG_ SAS_Status_Checksum : 7|8@0+ (1,0) [0|255] "Unitless"  ACM,EPAS_P,ESP,RCM,VDM
 SG_ SAS_Status_Counter : 11|4@0+ (1,0) [0|15] "Unitless"  ACM,EPAS_P,ESP,RCM,VDM
 SG_ SAS_StatusQ : 41|2@0+ (1,0) [0|3] ""  ACM,EPAS_P,ESP,RCM,VDM

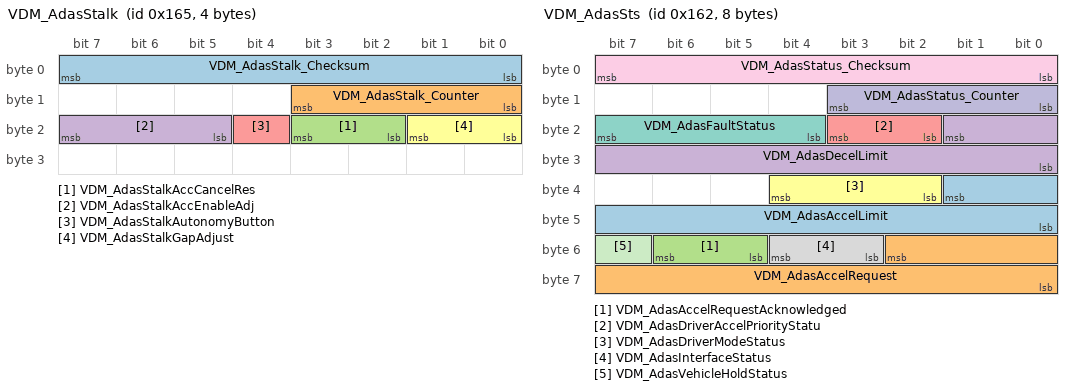
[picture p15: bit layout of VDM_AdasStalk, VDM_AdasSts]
BO_ 357 VDM_AdasStalk: 4 VDM
 SG_ VDM_AdasStalk_Checksum : 7|8@0+ (1,0) [0|255] "Unitless"  ACM
 SG_ VDM_AdasStalk_Counter : 11|4@0+ (1,0) [0|15] "Unitless"  ACM
 SG_ VDM_AdasStalkAccCancelRes : 19|2@0+ (1,0) [0|3] ""  ACM
 SG_ VDM_AdasStalkAccEnableAdj : 23|3@0+ (1,0) [0|7] ""  ACM
 SG_ VDM_AdasStalkAutonomyButton : 20|1@0+ (1,0) [0|1] ""  ACM
 SG_ VDM_AdasStalkGapAdjust : 17|2@0+ (1,0) [0|3] ""  ACM

BO_ 354 VDM_AdasSts: 8 VDM
 SG_ VDM_AdasAccelLimit : 33|10@0+ (0.01,0) [0|10.23] "m/s^2"  ACM
 SG_ VDM_AdasAccelRequest : 50|11@0+ (0.01,-10.24) [-10.24|10.23] "m/s^2"  ACM
 SG_ VDM_AdasAccelRequestAcknowledged : 54|2@0+ (1,0) [0|3] ""  ACM
 SG_ VDM_AdasDecelLimit : 17|10@0+ (0.01,0) [0|10.23] "m/s^2"  ACM
 SG_ VDM_AdasDriverAccelPriorityStatu : 19|2@0+ (1,0) [0|3] ""  ACM
 SG_ VDM_AdasDriverModeStatus : 36|3@0+ (1,0) [0|7] ""  ACM
 SG_ VDM_AdasFaultStatus : 23|4@0+ (1,0) [0|15] ""  ACM
 SG_ VDM_AdasInterfaceStatus : 52|2@0+ (1,0) [0|3] ""  ACM
 SG_ VDM_AdasStatus_Checksum : 7|8@0+ (1,0) [0|0] ""  ACM
 SG_ VDM_AdasStatus_Counter : 11|4@0+ (1,0) [0|0] ""  ACM
 SG_ VDM_AdasVehicleHoldStatus : 55|1@0+ (1,0) [0|1] ""  ACM

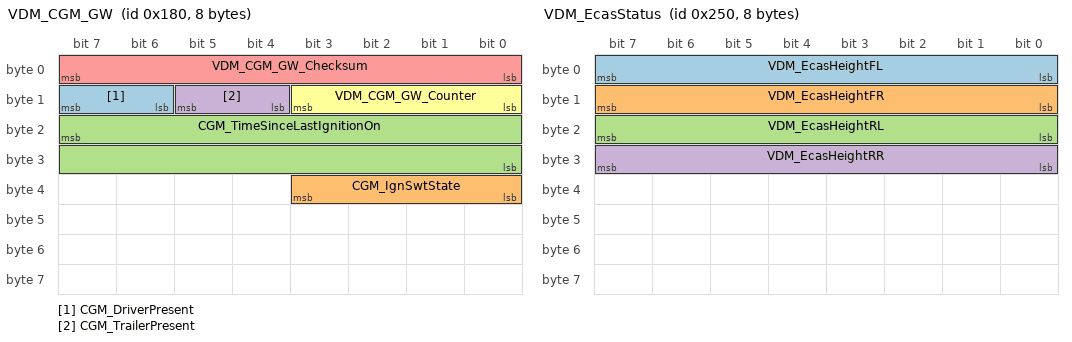
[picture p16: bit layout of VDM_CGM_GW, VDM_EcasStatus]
BO_ 384 VDM_CGM_GW: 8 CGM
 SG_ CGM_DriverPresent : 15|2@0+ (1,0) [0|3] ""  ESP,IBM
 SG_ CGM_IgnSwtState : 35|4@0+ (1,0) [0|15] ""  ESP,IBM
 SG_ CGM_TimeSinceLastIgnitionOn : 23|16@0+ (1,0) [0|65535] "s"  ESP,IBM
 SG_ CGM_TrailerPresent : 13|2@0+ (1,0) [0|3] ""  ESP,IBM
 SG_ VDM_CGM_GW_Checksum : 7|8@0+ (1,0) [0|0] ""  ESP,IBM
 SG_ VDM_CGM_GW_Counter : 11|4@0+ (1,0) [0|0] ""  ESP,IBM

BO_ 592 VDM_EcasStatus: 8 VDM
 SG_ VDM_EcasHeightFL : 7|8@0- (1,0) [-128|127] "mm"  ACM
 SG_ VDM_EcasHeightFR : 15|8@0- (1,0) [-128|127] "mm"  ACM
 SG_ VDM_EcasHeightRL : 23|8@0- (1,0) [-128|127] "mm"  ACM
 SG_ VDM_EcasHeightRR : 31|8@0- (1,0) [-128|127] "mm"  ACM

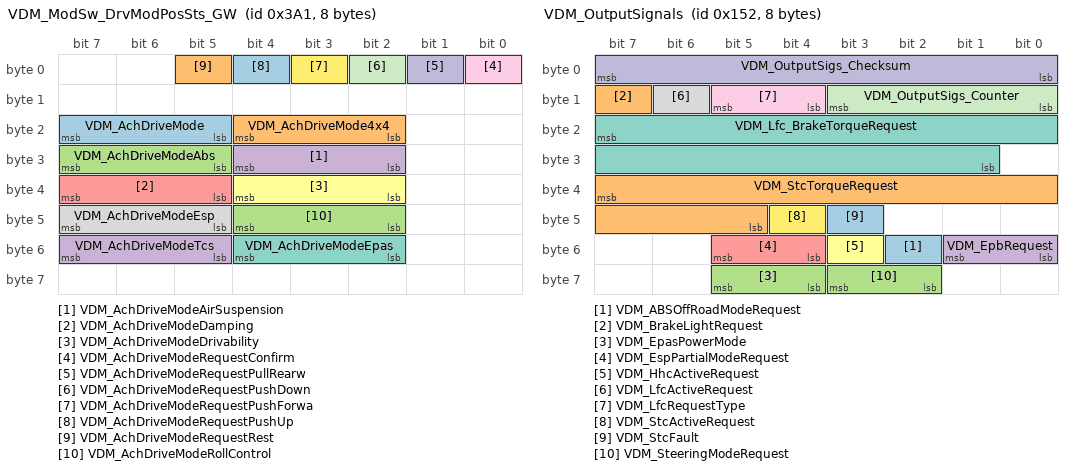
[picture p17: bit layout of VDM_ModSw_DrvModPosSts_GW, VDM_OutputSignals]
BO_ 929 VDM_ModSw_DrvModPosSts_GW: 8 VDM
 SG_ VDM_AchDriveMode : 23|3@0+ (1,0) [0|7] ""  ACM
 SG_ VDM_AchDriveMode4x4 : 20|3@0+ (1,0) [0|7] ""  ACM
 SG_ VDM_AchDriveModeAbs : 31|3@0+ (1,0) [0|7] ""  ACM
 SG_ VDM_AchDriveModeAirSuspension : 28|3@0+ (1,0) [0|7] ""  ACM
 SG_ VDM_AchDriveModeDamping : 39|3@0+ (1,0) [0|7] ""  ACM
 SG_ VDM_AchDriveModeDrivability : 36|3@0+ (1,0) [0|7] ""  ACM
 SG_ VDM_AchDriveModeEpas : 52|3@0+ (1,0) [0|7] ""  ACM
 SG_ VDM_AchDriveModeEsp : 47|3@0+ (1,0) [0|7] ""  ACM
 SG_ VDM_AchDriveModeRequestConfirm : 0|1@0+ (1,0) [0|1] ""  ACM
 SG_ VDM_AchDriveModeRequestPullRearw : 1|1@0+ (1,0) [0|1] ""  ACM
 SG_ VDM_AchDriveModeRequestPushDown : 2|1@0+ (1,0) [0|1] ""  ACM
 SG_ VDM_AchDriveModeRequestPushForwa : 3|1@0+ (1,0) [0|1] ""  ACM
 SG_ VDM_AchDriveModeRequestPushUp : 4|1@0+ (1,0) [0|1] ""  ACM
 SG_ VDM_AchDriveModeRequestRest : 5|1@0+ (1,0) [0|1] ""  ACM
 SG_ VDM_AchDriveModeRollControl : 44|3@0+ (1,0) [0|7] ""  ACM
 SG_ VDM_AchDriveModeTcs : 55|3@0+ (1,0) [0|7] ""  ACM

BO_ 338 VDM_OutputSignals: 8 VDM
 SG_ VDM_ABSOffRoadModeRequest : 50|1@0+ (1,0) [0|1] ""  ACM,EPAS_P,ESP,IBM,RCM
 SG_ VDM_BrakeLightRequest : 15|1@0+ (1,0) [0|0] ""  ACM,EPAS_P,ESP,IBM,RCM
 SG_ VDM_EpasPowerMode : 61|2@0+ (1,0) [0|3] ""  ACM,EPAS_P,ESP,IBM,RCM
 SG_ VDM_EpbRequest : 49|2@0+ (1,0) [0|3] ""  ACM,EPAS_P,ESP,IBM,RCM
 SG_ VDM_EspPartialModeRequest : 53|2@0+ (1,0) [0|3] ""  ACM,EPAS_P,ESP,IBM,RCM
 SG_ VDM_HhcActiveRequest : 51|1@0+ (1,0) [0|1] ""  ACM,EPAS_P,ESP,IBM,RCM
 SG_ VDM_Lfc_BrakeTorqueRequest : 23|15@0+ (2,-65534) [-65534|0] "Nm"  ACM,EPAS_P,ESP,IBM,RCM
 SG_ VDM_LfcActiveRequest : 14|1@0+ (1,0) [0|1] ""  ACM,EPAS_P,ESP,IBM,RCM
 SG_ VDM_LfcRequestType : 13|2@0+ (1,0) [0|3] ""  ACM,EPAS_P,ESP,IBM,RCM
 SG_ VDM_OutputSigs_Checksum : 7|8@0+ (1,0) [0|255] "Unitless"  ACM,EPAS_P,ESP,IBM,RCM
 SG_ VDM_OutputSigs_Counter : 11|4@0+ (1,0) [0|15] "Unitless"  ACM,EPAS_P,ESP,IBM,RCM
 SG_ VDM_StcActiveRequest : 44|1@0+ (1,0) [0|1] ""  ACM,EPAS_P,ESP,IBM,RCM
 SG_ VDM_StcFault : 43|1@0+ (1,0) [0|1] ""  ACM,EPAS_P,ESP,IBM,RCM
 SG_ VDM_StcTorqueRequest : 39|11@0+ (0.0078125,-8) [-8|7.9921875] "Nm"  ACM,EPAS_P,ESP,IBM,RCM
 SG_ VDM_SteeringModeRequest : 59|2@0+ (1,0) [0|3] ""  ACM,EPAS_P,ESP,IBM,RCM

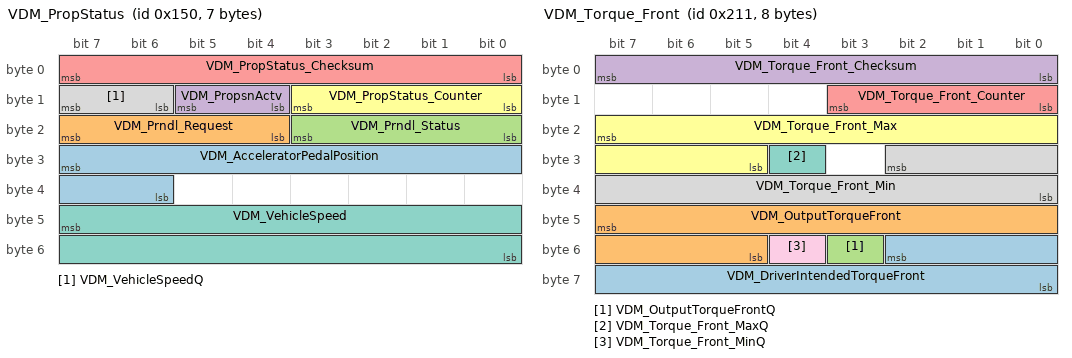
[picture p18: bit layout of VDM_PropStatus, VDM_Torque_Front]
BO_ 336 VDM_PropStatus: 7 VDM
 SG_ VDM_AcceleratorPedalPosition : 31|10@0+ (0.1,0) [0|102.3] ""  ACM,EPAS_P,ESP,RCM
 SG_ VDM_Prndl_Request : 23|4@0+ (1,0) [0|15] ""  ACM,EPAS_P,ESP,RCM
 SG_ VDM_Prndl_Status : 19|4@0+ (1,0) [0|15] ""  ACM,EPAS_P,ESP,RCM
 SG_ VDM_PropsnActv : 13|2@0+ (1,0) [0|3] ""  ACM,EPAS_P,ESP,RCM
 SG_ VDM_PropStatus_Checksum : 7|8@0+ (1,0) [0|255] "Unitless"  ACM,EPAS_P,ESP,RCM
 SG_ VDM_PropStatus_Counter : 11|4@0+ (1,0) [0|15] "Unitless"  ACM,EPAS_P,ESP,RCM
 SG_ VDM_VehicleSpeed : 47|16@0+ (0.01,0) [0|400] "Kph"  ACM,EPAS_P,ESP,RCM
 SG_ VDM_VehicleSpeedQ : 15|2@0+ (1,0) [0|3] ""  ACM,EPAS_P,ESP,RCM

BO_ 529 VDM_Torque_Front: 8 VDM
 SG_ VDM_DriverIntendedTorqueFront : 50|11@0+ (1,-1023) [-1023|1024] "Nm"  ESP
 SG_ VDM_OutputTorqueFront : 47|11@0+ (1,-1023) [-1023|1024] "Nm"  ESP
 SG_ VDM_OutputTorqueFrontQ : 51|1@0+ (1,0) [0|1] ""  ESP
 SG_ VDM_Torque_Front_Checksum : 7|8@0+ (1,0) [0|255] "Unitless"  ESP
 SG_ VDM_Torque_Front_Counter : 11|4@0+ (1,0) [0|15] "Unitless"  ESP
 SG_ VDM_Torque_Front_Max : 23|11@0+ (1,-1023) [-1023|1024] "Nm"  ESP
 SG_ VDM_Torque_Front_MaxQ : 28|1@0+ (1,0) [0|1] ""  ESP
 SG_ VDM_Torque_Front_Min : 26|11@0+ (1,-1023) [-1023|1024] "Nm"  ESP
 SG_ VDM_Torque_Front_MinQ : 52|1@0+ (1,0) [0|1] ""  ESP

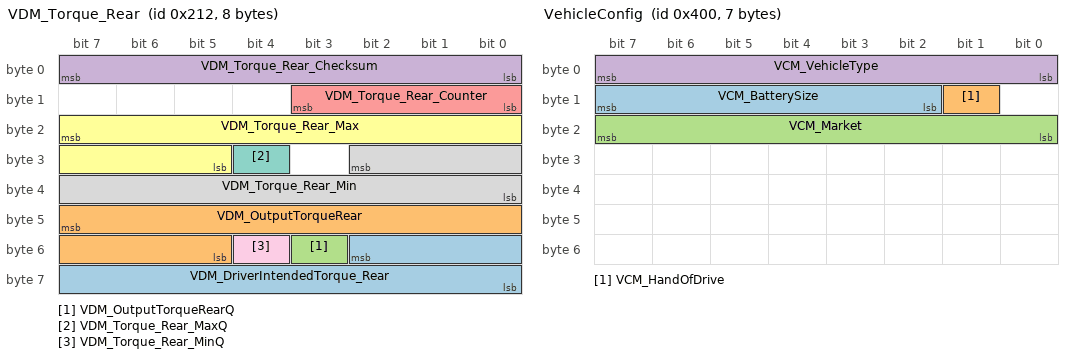
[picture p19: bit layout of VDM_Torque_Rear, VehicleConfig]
BO_ 530 VDM_Torque_Rear: 8 VDM
 SG_ VDM_DriverIntendedTorque_Rear : 50|11@0+ (1,-1023) [-1023|1024] "Nm"  ESP
 SG_ VDM_OutputTorqueRear : 47|11@0+ (1,-1023) [-1023|1024] "Nm"  ESP
 SG_ VDM_OutputTorqueRearQ : 51|1@0+ (1,0) [0|1] ""  ESP
 SG_ VDM_Torque_Rear_Checksum : 7|8@0+ (1,0) [0|255] "Unitless"  ESP
 SG_ VDM_Torque_Rear_Counter : 11|4@0+ (1,0) [0|15] "Unitless"  ESP
 SG_ VDM_Torque_Rear_Max : 23|11@0+ (1,-1023) [-1023|1024] "Nm"  ESP
 SG_ VDM_Torque_Rear_MaxQ : 28|1@0+ (1,0) [0|1] ""  ESP
 SG_ VDM_Torque_Rear_Min : 26|11@0+ (1,-1023) [-1023|1024] "Nm"  ESP
 SG_ VDM_Torque_Rear_MinQ : 52|1@0+ (1,0) [0|1] ""  ESP

BO_ 1024 VehicleConfig: 7 CGM
 SG_ VCM_BatterySize : 15|6@0+ (1,0) [0|63] ""  ACM,ESP
 SG_ VCM_HandOfDrive : 9|1@0+ (1,0) [0|1] ""  ACM,ESP
 SG_ VCM_Market : 23|8@0+ (1,0) [0|255] ""  ACM,ESP
 SG_ VCM_VehicleType : 7|8@0+ (1,0) [0|255] ""  ACM,ESP

BO_ 1635 XCP_Cmd_EPAS_P: 8 TestTool

BO_ 1545 XCP_Cmd_VDM: 8 TestTool

BO_ 1636 XCP_Daq_EPAS_P: 8 EPAS_P

BO_ 1705 XCP_Daq_VDM: 8 VDM

BO_ 1637 XCP_Resp_EPAS_P: 8 EPAS_P

BO_ 1609 XCP_Resp_VDM: 8 VDM

BA_DEF_  "Baudrate" FLOAT 1000 1000000;
BA_DEF_ BO_  "GenMsgSendType" ENUM  "cyclic","spontaneous","cyclicIfActive","spontaneousWithDelay","cyclicAndSpontaneous","cyclicAndSpontaneousWithDelay","IfActive","NoMsgSendType";
BA_DEF_ BO_  "GenMsgCycleTime" FLOAT 0 300000;
BA_DEF_ BO_  "GenMsgStartDelayTime" FLOAT 0 300000;
BA_DEF_ BO_  "GenMsgDelayTime" FLOAT 0 300000;
BA_DEF_ SG_  "GenSigSendType" ENUM  "Cyclic","OnWrite","OnWriteWithRepetition","OnChange","OnChangeWithRepetition","IfActive","IfActiveWithRepetition","NoSigSendType";
BA_DEF_ SG_  "GenSigStartValue" FLOAT -1.79769313486232E+308 1.84467440737096E+019;
BA_DEF_  "DBName" STRING ;
BA_DEF_  "BusType" STRING ;
BA_DEF_  "ProtocolType" STRING ;
BA_DEF_ BO_  "SystemMessageLongSymbol" STRING ;
BA_DEF_DEF_  "Baudrate" 1000;
BA_DEF_DEF_  "GenMsgSendType" "";
BA_DEF_DEF_  "GenMsgCycleTime" 0;
BA_DEF_DEF_  "GenMsgStartDelayTime" 0;
BA_DEF_DEF_  "GenMsgDelayTime" 0;
BA_DEF_DEF_  "GenSigSendType" "Cyclic";
BA_DEF_DEF_  "GenSigStartValue" 0;
BA_DEF_DEF_  "DBName" "";
BA_DEF_DEF_  "BusType" "";
BA_DEF_DEF_  "ProtocolType" "";
BA_DEF_DEF_  "SystemMessageLongSymbol" "";
BA_ "Baudrate" 500000;
BA_ "ProtocolType" "CAN";
BA_ "BusType" "CAN";
BA_ "DBName" "PrimaryActuatorCAN";
BA_ "GenMsgCycleTime" BO_ 257 10;
BA_ "GenMsgSendType" BO_ 257 0;
BA_ "GenMsgCycleTime" BO_ 288 10;
BA_ "GenMsgSendType" BO_ 288 0;
BA_ "GenMsgCycleTime" BO_ 352 10;
BA_ "GenMsgSendType" BO_ 352 0;
BA_ "GenMsgCycleTime" BO_ 256 10;
BA_ "GenMsgSendType" BO_ 256 0;
BA_ "GenMsgCycleTime" BO_ 272 10;
BA_ "GenMsgSendType" BO_ 272 0;
BA_ "GenMsgCycleTime" BO_ 880 10;
BA_ "GenMsgSendType" BO_ 880 0;
BA_ "GenMsgSendType" BO_ 789 1;
BA_ "GenMsgDelayTime" BO_ 1800 10;
BA_ "GenMsgSendType" BO_ 1800 1;
BA_ "SystemMessageLongSymbol" BO_ 1800 "Diag_PhysReq_ACM_PrimaryActuatorCAN";
BA_ "GenMsgDelayTime" BO_ 1843 10;
BA_ "GenMsgSendType" BO_ 1843 1;
BA_ "SystemMessageLongSymbol" BO_ 1843 "Diag_PhysReq_EPAS_P_PrimaryActuatorCAN";
BA_ "GenMsgDelayTime" BO_ 1845 10;
BA_ "GenMsgSendType" BO_ 1845 1;
BA_ "SystemMessageLongSymbol" BO_ 1845 "Diag_PhysReq_ESP_PrimaryActuatorCAN";
BA_ "GenMsgDelayTime" BO_ 1846 10;
BA_ "GenMsgSendType" BO_ 1846 1;
BA_ "SystemMessageLongSymbol" BO_ 1846 "Diag_PhysReq_IBM_PrimaryActuatorCAN";
BA_ "GenMsgDelayTime" BO_ 1844 10;
BA_ "GenMsgSendType" BO_ 1844 1;
BA_ "SystemMessageLongSymbol" BO_ 1844 "Diag_PhysReq_RCM_PrimaryActuatorCAN";
BA_ "GenMsgDelayTime" BO_ 1864 10;
BA_ "GenMsgSendType" BO_ 1864 1;
BA_ "SystemMessageLongSymbol" BO_ 1864 "Diag_PhysResp_ACM_PrimaryActuatorCAN";
BA_ "GenMsgDelayTime" BO_ 1907 10;
BA_ "GenMsgSendType" BO_ 1907 1;
BA_ "SystemMessageLongSymbol" BO_ 1907 "Diag_PhysResp_EPAS_P_PrimaryActuatorCAN";
BA_ "GenMsgDelayTime" BO_ 1909 10;
BA_ "GenMsgSendType" BO_ 1909 1;
BA_ "SystemMessageLongSymbol" BO_ 1909 "Diag_PhysResp_ESP_PrimaryActuatorCAN";
BA_ "GenMsgDelayTime" BO_ 1910 10;
BA_ "GenMsgSendType" BO_ 1910 1;
BA_ "SystemMessageLongSymbol" BO_ 1910 "Diag_PhysResp_IBM_PrimaryActuatorCAN";
BA_ "GenMsgDelayTime" BO_ 1908 10;
BA_ "GenMsgSendType" BO_ 1908 1;
BA_ "SystemMessageLongSymbol" BO_ 1908 "Diag_PhysResp_RCM_PrimaryActuatorCAN";
BA_ "GenMsgCycleTime" BO_ 1328 100;
BA_ "GenMsgSendType" BO_ 1328 0;
BA_ "GenMsgCycleTime" BO_ 1329 100;
BA_ "GenMsgSendType" BO_ 1329 0;
BA_ "GenMsgCycleTime" BO_ 1330 100;
BA_ "GenMsgSendType" BO_ 1330 0;
BA_ "GenMsgCycleTime" BO_ 912 10;
BA_ "GenMsgSendType" BO_ 912 0;
BA_ "GenMsgCycleTime" BO_ 896 10;
BA_ "GenMsgSendType" BO_ 896 0;
BA_ "GenMsgCycleTime" BO_ 848 20;
BA_ "GenMsgSendType" BO_ 848 0;
BA_ "GenMsgSendType" BO_ 864 1;
BA_ "GenMsgCycleTime" BO_ 258 10;
BA_ "GenMsgSendType" BO_ 258 0;
BA_ "GenMsgCycleTime" BO_ 524 20;
BA_ "GenMsgSendType" BO_ 524 0;
BA_ "GenMsgCycleTime" BO_ 811 40;
BA_ "GenMsgSendType" BO_ 811 0;
BA_ "GenMsgCycleTime" BO_ 520 20;
BA_ "GenMsgSendType" BO_ 520 0;
BA_ "GenMsgCycleTime" BO_ 432 10;
BA_ "GenMsgSendType" BO_ 432 0;
BA_ "GenMsgCycleTime" BO_ 448 10;
BA_ "GenMsgSendType" BO_ 448 0;
BA_ "GenMsgCycleTime" BO_ 523 10;
BA_ "GenMsgSendType" BO_ 523 0;
BA_ "GenMsgCycleTime" BO_ 521 5;
BA_ "GenMsgSendType" BO_ 521 0;
BA_ "GenMsgCycleTime" BO_ 522 5;
BA_ "GenMsgSendType" BO_ 522 0;
BA_ "GenMsgCycleTime" BO_ 907 20;
BA_ "GenMsgSendType" BO_ 907 0;
BA_ "GenMsgCycleTime" BO_ 908 10;
BA_ "GenMsgSendType" BO_ 908 0;
BA_ "GenMsgCycleTime" BO_ 909 10;
BA_ "GenMsgSendType" BO_ 909 0;
BA_ "GenMsgCycleTime" BO_ 910 10;
BA_ "GenMsgSendType" BO_ 910 0;
BA_ "GenMsgCycleTime" BO_ 911 20;
BA_ "GenMsgSendType" BO_ 911 0;
BA_ "GenMsgCycleTime" BO_ 1640 500;
BA_ "GenMsgSendType" BO_ 1640 0;
BA_ "GenMsgCycleTime" BO_ 516 500;
BA_ "GenMsgSendType" BO_ 516 0;
BA_ "GenMsgCycleTime" BO_ 1280 1000;
BA_ "GenMsgSendType" BO_ 1280 0;
BA_ "GenMsgCycleTime" BO_ 309 20;
BA_ "GenMsgSendType" BO_ 309 0;
BA_ "GenMsgCycleTime" BO_ 304 10;
BA_ "GenMsgSendType" BO_ 304 0;
BA_ "GenMsgCycleTime" BO_ 320 10;
BA_ "GenMsgSendType" BO_ 320 0;
BA_ "GenMsgCycleTime" BO_ 1281 100;
BA_ "GenMsgSendType" BO_ 1281 0;
BA_ "GenMsgCycleTime" BO_ 826 120;
BA_ "GenMsgSendType" BO_ 826 0;
BA_ "GenMsgCycleTime" BO_ 64 10;
BA_ "GenMsgSendType" BO_ 64 0;
BA_ "GenMsgCycleTime" BO_ 357 20;
BA_ "GenMsgSendType" BO_ 357 0;
BA_ "GenMsgCycleTime" BO_ 354 10;
BA_ "GenMsgSendType" BO_ 354 0;
BA_ "GenMsgCycleTime" BO_ 384 50;
BA_ "GenMsgSendType" BO_ 384 0;
BA_ "GenMsgCycleTime" BO_ 592 20;
BA_ "GenMsgSendType" BO_ 592 0;
BA_ "GenMsgCycleTime" BO_ 929 40;
BA_ "GenMsgSendType" BO_ 929 0;
BA_ "GenMsgCycleTime" BO_ 338 10;
BA_ "GenMsgSendType" BO_ 338 0;
BA_ "GenMsgCycleTime" BO_ 336 20;
BA_ "GenMsgSendType" BO_ 336 0;
BA_ "GenMsgCycleTime" BO_ 529 10;
BA_ "GenMsgSendType" BO_ 529 0;
BA_ "GenMsgCycleTime" BO_ 530 10;
BA_ "GenMsgSendType" BO_ 530 0;
BA_ "GenMsgCycleTime" BO_ 1024 100;
BA_ "GenMsgSendType" BO_ 1024 0;
BA_ "GenMsgSendType" BO_ 1635 1;
BA_ "GenMsgDelayTime" BO_ 1545 10;
BA_ "GenMsgSendType" BO_ 1545 1;
BA_ "GenMsgSendType" BO_ 1636 1;
BA_ "GenMsgDelayTime" BO_ 1705 10;
BA_ "GenMsgSendType" BO_ 1705 1;
BA_ "GenMsgSendType" BO_ 1637 1;
BA_ "GenMsgDelayTime" BO_ 1609 10;
BA_ "GenMsgSendType" BO_ 1609 1;
BA_ "GenSigStartValue" SG_ 288 ACM_lkaStrToqReq 1024;
BA_ "GenSigStartValue" SG_ 352 ACM_AccelerationRequest 1024;
BA_ "GenSigStartValue" SG_ 272 ACM_SteeringAngleRequest 16384;
BA_ "GenSigStartValue" SG_ 912 EPAS_InternalSas 8192;
BA_ "GenSigStartValue" SG_ 896 EPAS_TorsionBarTorque 2050;
BA_ "GenSigStartValue" SG_ 309 RCM_IMU_Heave 32768;
BA_ "GenSigStartValue" SG_ 309 RCM_IMU_Roll 32768;
BA_ "GenSigStartValue" SG_ 304 RCM_IMU_LatAcc 32768;
BA_ "GenSigStartValue" SG_ 304 RCM_IMU_Yaw 32768;
BA_ "GenSigStartValue" SG_ 320 RCM_IMU_LongAcc_Sig 32768;
BA_ "GenSigStartValue" SG_ 826 RCM_Status_IND_WARN_RCM 1;
BA_ "GenSigStartValue" SG_ 529 VDM_DriverIntendedTorqueFront 1023;
BA_ "GenSigStartValue" SG_ 529 VDM_OutputTorqueFront 1023;
BA_ "GenSigStartValue" SG_ 529 VDM_Torque_Front_Max 1023;
BA_ "GenSigStartValue" SG_ 529 VDM_Torque_Front_Min 1023;
BA_ "GenSigStartValue" SG_ 530 VDM_DriverIntendedTorque_Rear 1023;
BA_ "GenSigStartValue" SG_ 530 VDM_OutputTorqueRear 1023;
BA_ "GenSigStartValue" SG_ 530 VDM_Torque_Rear_Max 1023;
BA_ "GenSigStartValue" SG_ 530 VDM_Torque_Rear_Min 1023;
VAL_ 257 ACM_DbsLevel 0 "ACM_DbsLevel_No_Activation" 1 "ACM_DbsLevel_Level_1" 2 "ACM_DbsLevel_Level_2" 3 "ACM_DbsLevel_Level_3" ;
VAL_ 257 ACM_EnableRequest 0 "ACM_EnableRequest_Disable" 1 "ACM_EnableRequest_Enable" ;
VAL_ 257 ACM_FailInfo 0 "ACM_FailInfo_Normal" 1 "ACM_FailInfo_Temp_Unav_By_Camera" 2 "ACM_FailInfo_Temp_Unav_By_Radar" 3 "ACM_FailInfo_Service_Required" ;
VAL_ 257 ACM_OnOffStatus 0 "ACM_OnOffStatus_Off" 1 "ACM_OnOffStatus_On_Fcw" 2 "ACM_OnOffStatus_On_Aeb" 3 "ACM_OnOffStatus_Invalid" ;
VAL_ 257 ACM_PrefillEnableRequest 0 "ACM_PrefillEnableRequest_Disable" 1 "ACM_PrefillEnableRequest_Enable" ;
VAL_ 257 ACM_StopRequest 0 "ACM_StopRequest_No_Request" 1 "ACM_StopRequest_Request" ;
VAL_ 257 ACM_WarnLevel 0 "ACM_WarnLevel_No_Warning" 1 "ACM_WarnLevel_Warning_Level_1" 2 "ACM_WarnLevel_Warning_Level_2" 3 "ACM_WarnLevel_Warning_Level_3" ;
VAL_ 288 ACM_FailinfoAeb 0 "ACM_FAILINFOAEB_NORMAL" 1 "ACM_FAILINFOAEB_CAMERA_FAILURE" 2 "ACM_FAILINFOAEB_FRONT_RADAR_COM_ERR" 3 "ACM_FAILINFOAEB_CAMERA_BLOCKAGE" 4 "ACM_FAILINFOAEB_RESERVED_4" 5 "ACM_FAILINFOAEB_RESERVED_5" 6 "ACM_FAILINFOAEB_RESERVED_6" ;
VAL_ 288 ACM_HapticRequest 0 "ACM_HapticRequest_No_Request" 1 "ACM_HapticRequest_Haptic_Request" ;
VAL_ 288 ACM_hbaLamp 0 "ACM_HBALAMP_HBA_INDICATOR_LAMP_OFF" 1 "ACM_HBALAMP_HBA_INDICATOR_LAMP_ON" ;
VAL_ 288 ACM_hbaOpt 0 "ACM_HBAOPT_NONE_HBA_OPTION_DEFAULT" 1 "ACM_HBAOPT_HBA_SYSTEM_ENABLE" ;
VAL_ 288 ACM_hbaSysState 0 "ACM_HBASYSSTATE_DEFAULT_DISABLE" 1 "ACM_HBASYSSTATE_HBA_ENABLE_HIGH_BEAM_OFF" 2 "ACM_HBASYSSTATE_HBA_ENABLE_HIGH_BEAM_ON" 7 "ACM_HBASYSSTATE_SYSTEM_FAIL" ;
VAL_ 288 ACM_lkaActToi 0 "ACM_LKAACTTOI_DE_ACTIVATE_TOI" 1 "ACM_LKAACTTOI_ACTIVATE_TOI" ;
VAL_ 288 ACM_lkaHandsoffDisplayWarning 0 "ACM_LKAHANDSOFFDISPLAYWARNING_NO_INFO" 1 "ACM_LKAHANDSOFFDISPLAYWARNING_WARNING" 2 "ACM_LKAHANDSOFFDISPLAYWARNING_RESERVED_2" 3 "ACM_LKAHANDSOFFDISPLAYWARNING_RESERVED_3" ;
VAL_ 288 ACM_lkaHandsoffSoundWarning 0 "ACM_LKAHANDSOFFSOUNDWARNING_NO_INFO" 1 "ACM_LKAHANDSOFFSOUNDWARNING_WARNING" 2 "ACM_LKAHANDSOFFSOUNDWARNING_RESERVED_2" 3 "ACM_LKAHANDSOFFSOUNDWARNING_RESERVED_3" ;
VAL_ 288 ACM_lkaLaneRecogState 0 "ACM_LKALANERECOGSTATE_NOT_RECOGNITION" 1 "ACM_LKALANERECOGSTATE_LEFT_LANE_RECOGNITION" 2 "ACM_LKALANERECOGSTATE_RIGHT_LANE_RECOGNITION" 3 "ACM_LKALANERECOGSTATE_FULL_LANE_RECOGNITION" ;
VAL_ 288 ACM_lkaLHWarning 0 "ACM_LKALHWARNING_NO_WARNING" 1 "ACM_LKALHWARNING_HAPTIC_WARNING_AND_DISPLAY" 2 "ACM_LKALHWARNING_ACOUSTIC_WARNING_AND_DISPLAY" 3 "ACM_LKALHWARNING_HAPTIC_ACOUSTIC_AND_DISPLAY" ;
VAL_ 288 ACM_lkaRHWarning 0 "ACM_LKARHWARNING_NO_WARNING" 1 "ACM_LKARHWARNING_HAPTIC_WARNING_AND_DISPLAY" 2 "ACM_LKARHWARNING_ACOUSTIC_WARNING_AND_DISPLAY" 3 "ACM_LKARHWARNING_HAPTIC_ACOUSTIC_AND_DISPLAY" ;
VAL_ 288 ACM_lkaSymbolState 0 "ACM_LKASYMBOLSTATE_OFF" 1 "ACM_LKASYMBOLSTATE_WHITE_ON_LDW_STANDBY" 2 "ACM_LKASYMBOLSTATE_GREEN_ON_LDW_LKA_STANDBY" 3 "ACM_LKASYMBOLSTATE_GREEN_BLNK_LDW_WARN_OR_LKA_CNTRL" 4 "ACM_LKASYMBOLSTATE_ORANGE_ON_FAIL" 5 "ACM_LKASYMBOLSTATE_ORANGE_BLINK_NOT_CALIBRATED" 6 "ACM_LKASYMBOLSTATE_ORANGE_ON_REGULATION" 7 "ACM_LKASYMBOLSTATE_WHITE_BLINK" ;
VAL_ 288 ACM_lkaToiFlt 0 "ACM_LKATOIFLT_NO_FAULT" 1 "ACM_LKATOIFLT_FAULT_PRESENT" ;
VAL_ 352 ACM_AccelerationRequestType 0 "ACM_ACCELREQTYPE_INIT" 1 "ACM_ACCELREQTYPE_ACCEL_NEGATIVE" 2 "ACM_ACCELREQTYPE_ACCEL_POSITIVE" 3 "ACM_ACCELREQTYPE_SNA" ;
VAL_ 352 ACM_longInterfaceEnable 0 "ACM_LONGIFEN_INIT" 1 "ACM_LONGIFEN_LONGITUDINAL_INTERFACE_ENABLE" 2 "ACM_LONGIFEN_LONGITUDINAL_INTERFACE_DISABLE" 3 "ACM_LONGIFEN_SNA" ;
VAL_ 352 ACM_PrndRequired 0 "ACM_PRNDREQ_PARK" 1 "ACM_PRNDREQ_REVERSE" 2 "ACM_PRNDREQ_NEUTRAL" 3 "ACM_PRNDREQ_DRIVE" 4 "ACM_PRNDREQ_NOT_USED" ;
VAL_ 352 ACM_VehicleHoldRequired 0 "ACM_VEHICLEHOLDREQ_NO_REQUEST" 1 "ACM_VEHICLEHOLDREQ_VEHICLE_HOLD_REQUEST" ;
VAL_ 256 ACM_FaultStatus 0 "ACM_FaultStatus_NoFault" 1 "ACM_FaultStatus_Faulted" 7 "ACM_FaultStatus_Sna" ;
VAL_ 256 ACM_FeatureStatus 0 "ACM_FeatureStatus_Standby" 1 "ACM_FeatureStatus_Acc" 2 "ACM_FeatureStatus_Hwp" 3 "ACM_FeatureStatus_Uf" 4 "ACM_FeatureStatus_Faulted" ;
VAL_ 272 ACM_EacEnabled 0 "ACM_EacEnable_None" 1 "ACM_EacEnable_Enabled" 2 "ACM_EacEnable_Reserved" ;
VAL_ 272 ACM_HapticRequired 0 "ACM_HapticRequired_Inactive" 1 "ACM_HapticRequired_Active" ;
VAL_ 880 ACM_tsrAddInfoDisplay 0 "ACM_TSRADDINFODISPLAY_NONE_DISPLAY_DEFAULT" 1 "ACM_TSRADDINFODISPLAY_LHD_NO_PASSING_ZONE_DISPLAY" 2 "ACM_TSRADDINFODISPLAY_RHD_NO_PASSING_ZONE_DISPLAY" 3 "ACM_TSRADDINFODISPLAY_INVALID" ;
VAL_ 880 ACM_tsrConInfoStaCon1 0 "ACM_TSRCONINFOSTACON1_NONE_DEFAULT" 1 "ACM_TSRCONINFOSTACON1_RAIN" 2 "ACM_TSRCONINFOSTACON1_SNOW" 3 "ACM_TSRCONINFOSTACON1_SNOW_RAIN" 4 "ACM_TSRCONINFOSTACON1_TARILER" 5 "ACM_TSRCONINFOSTACON1_DISTANCE" 6 "ACM_TSRCONINFOSTACON1_TIME" 7 "ACM_TSRCONINFOSTACON1_FOG" 8 "ACM_TSRCONINFOSTACON1_RESERVED_8" 9 "ACM_TSRCONINFOSTACON1_RESERVED_9" 10 "ACM_TSRCONINFOSTACON1_RESERVED_10" 11 "ACM_TSRCONINFOSTACON1_RESERVED_11" 12 "ACM_TSRCONINFOSTACON1_RESERVED_12" 14 "ACM_TSRCONINFOSTACON1_GENERIC" 15 "ACM_TSRCONINFOSTACON1_RESERVED_15" ;
VAL_ 880 ACM_tsrConInfoStaCon2 0 "ACM_TSRCONINFOSTACON2_NONE_DEFAULT" 1 "ACM_TSRCONINFOSTACON2_RAIN" 2 "ACM_TSRCONINFOSTACON2_SNOW" 3 "ACM_TSRCONINFOSTACON2_SNOW_RAIN" 4 "ACM_TSRCONINFOSTACON2_TARILER" 5 "ACM_TSRCONINFOSTACON2_DISTANCE" 6 "ACM_TSRCONINFOSTACON2_TIME" 7 "ACM_TSRCONINFOSTACON2_FOG" 8 "ACM_TSRCONINFOSTACON2_RESERVED_8" 9 "ACM_TSRCONINFOSTACON2_RESERVED_9" 10 "ACM_TSRCONINFOSTACON2_RESERVED_10" 11 "ACM_TSRCONINFOSTACON2_RESERVED_11" 12 "ACM_TSRCONINFOSTACON2_RESERVED_12" 14 "ACM_TSRCONINFOSTACON2_GENERIC" 15 "ACM_TSRCONINFOSTACON2_RESERVED_15" ;
VAL_ 880 ACM_tsrOvrlapSignDis 0 "ACM_TSROVRLAPSIGNDIS_NONE_DEFAULT" 1 "ACM_TSROVRLAPSIGNDIS_OVERLAP_SIGN" 2 "ACM_TSROVRLAPSIGNDIS_RESERVED" ;
VAL_ 880 ACM_tsrSpdDisClsMain 0 "TSR_Speed_No_Recognition_Default" 253 "TSR_Speed_Unlimited_Speed" 254 "TSR_Speed_Reserved" 255 "TSR_Speed_Invalid" ;
VAL_ 880 ACM_tsrSpdDisCluCon1 0 "ACM_TSRSPDDISCLUCON1_NO_RECOGNITION_DEFAULT" 1 "ACM_TSRSPDDISCLUCON1_A1_252_PH_1XHEX_KPHORMPH" 253 "ACM_TSRSPDDISCLUCON1_LHD_CONDITIONAL_NO_PASSING_ZONE" 254 "ACM_TSRSPDDISCLUCON1_RHD_CONDITIONAL_NO_PASSING_ZONE" 255 "ACM_TSRSPDDISCLUCON1_INVALID" ;
VAL_ 880 ACM_tsrSpdDisCluCon2 0 "ACM_TSRSPDDISCLUCON2_NO_RECOGNITION_DEFAULT" 1 "ACM_TSRSPDDISCLUCON2_A1_252_PH_1XHEX_KPHORMPH" 253 "ACM_TSRSPDDISCLUCON2_LHD_CONDITIONAL_NO_PASSING_ZONE" 254 "ACM_TSRSPDDISCLUCON2_RHD_CONDITIONAL_NO_PASSING_ZONE" 255 "ACM_TSRSPDDISCLUCON2_INVALID" ;
VAL_ 880 ACM_tsrSpdDisCluConM 0 "ACM_TSRSPDDISCLUCONM_NO_RECOGNITION_DEFAULT" 253 "ACM_TSRSPDDISCLUCONM_UNLIMITED_SPEED" 254 "ACM_TSRSPDDISCLUCONM_RESERVED" 255 "ACM_TSRSPDDISCLUCONM_INVALID" ;
VAL_ 880 ACM_tsrStatus 0 "ACM_TSRSTATUS_TSR_INFORMATION_VALID_DEFAULT" 1 "ACM_TSRSTATUS_TSR_INFORMATION_INVALID_FAILURE" 2 "ACM_TSRSTATUS_TSR_INFORMATION_TEMPORARY_UNAVAILABLE" ;
VAL_ 912 EPAS_EacErrorCode 0 "EPAS_No_Err" 1 "EPAS_High_Angle_Cmd_Err" 2 "EPAS_High_Actual_Angle_Err" 3 "EPAS_High_Actual_Angle_Rate_Err" 4 "EPAS_Feature_Fault_Err" 5 "EPAS_Feature_Status_Invalid_Err" 6 "EPAS_Feature_Angle_Thd_Err" 7 "EPAS_Angle_Control_Cntr_Err" 8 "EPAS_Angle_Control_Mia_Err" 9 "EPAS_Angle_Control_Crc_Err" 10 "EPAS_Vehspd_Corrln_Failr_Err" 11 "EPAS_Vehspd_Max_Thd_Err" 12 "EPAS_Hands_On_Detn_Err" 13 "EPAS_Ext_Angle_Plausibility_Err" 14 "EPAS_High_Delta_Angle_Err" 15 "EPAS_Max_Steady_State_Err" ;
VAL_ 912 EPAS_EacStatus 0 "EPAS_EacStatus_Eac_Inhibited" 1 "EPAS_EacStatus_Eac_Available" 2 "EPAS_EacStatus_Eac_Active" 3 "EPAS_EacStatus_Eac_Standby" 4 "EPAS_EacStatus_Eac_Fault" 5 "EPAS_EacStatus_Sna" ;
VAL_ 912 EPAS_InternalSasQ 0 "EPAS_INTERNALSASQF_VALID" 1 "EPAS_INTERNALSASQF_INVALID" ;
VAL_ 896 EPAS_HandsOnLevel 0 "EPAS_HandsOnLevel_Level_0" 1 "EPAS_HandsOnLevel_Level_1" 2 "EPAS_HandsOnLevel_Level_2" 3 "EPAS_HandsOnLevel_Level_3" ;
VAL_ 896 EPAS_StcActive 0 "Stc_NotActive" 1 "Stc_Active" ;
VAL_ 896 EPAS_StcFault 0 "Stc_NoFault" 1 "Stc_Fault" ;
VAL_ 896 EPAS_StcUnavailable 0 "Stc_Available" 1 "Stc_Unavailable" ;
VAL_ 896 EPAS_SteeringFault 0 "EPAS_SteeringFault_No_Fault" 1 "EPAS_SteeringFault_Fault" ;
VAL_ 896 EPAS_SteeringMode 0 "EPASP_SteeringMode_Default" 1 "EPASP_SteeringMode_Normal" 2 "EPASP_SteeringMode_Sport" 3 "EPASP_SteeringMode_Comfort" ;
VAL_ 896 EPAS_SteeringReduced 0 "EPAS_EPAS_SteeringReduced_Normal_Assist" 1 "EPAS_EPAS_SteeringReduced_Reduced_Assist" ;
VAL_ 896 H_CAN_EPS_ToiUnavailable 0 "H_CAN_EPS_ToiUnavailable_Available" 1 "H_CAN_EPS_ToiUnavailable_Unavailable" ;
VAL_ 896 H_CAN_EPSS_ToiActive 0 "H_CAN_EPS_ToiActive_Deactivated" 1 "H_CAN_EPS_ToiActive_Activated" ;
VAL_ 896 H_CAN_EPSS_ToiFlt 0 "H_CAN_EPS_ToiFault_No_Fault" 1 "H_CAN_EPS_ToiFault_Fault" ;
VAL_ 848 EPAS_Ecu1EacSts 0 "EPAS_Ecu1EacSts_Eac_Inhibited" 1 "EPAS_Ecu1EacSts_Eac_Available" 2 "EPAS_Ecu1EacSts_Eac_Active" 3 "EPAS_Ecu1EacSts_Eac_Fault" 7 "EPAS_Ecu1EacSts_Sna" ;
VAL_ 848 EPAS_Ecu1PowerMode 0 "EPASP_powerMode_Drive_Off" 1 "EPASP_powerMode_Drive_On" 2 "EPASP_powerMode_Shutdown" 3 "EPASP_powerMode_Sna" ;
VAL_ 848 EPAS_Ecu1Role 0 "EPASP_ROLE_MASTER" 1 "EPASP_ROLE_SLAVE" 2 "EPASP_ROLE_RESERVED" ;
VAL_ 848 EPAS_Ecu1State 0 "EPAS_Ecu1State_Initialisation_Arbitration" 1 "EPAS_Ecu1State_Reserved" 2 "EPAS_Ecu1State_Reserved1" 3 "EPAS_Ecu1State_Initialisation_Complete" 4 "EPAS_Ecu1State_Passive" 5 "EPAS_Ecu1State_Passive_Faulted" 6 "EPAS_Ecu1State_Assist_Active" 7 "EPAS_Ecu1State_Assist_Standby" 8 "EPAS_Ecu1State_Eac_Active" 9 "EPAS_Ecu1State_Eac_Standby" 15 "EPAS_Ecu1State_Invalid" ;
VAL_ 864 EPAS_Ecu2EacSts 0 "EPAS_Ecu2EacSts_Eac_Inhibited" 1 "EPAS_Ecu2EacSts_Eac_Available" 2 "EPAS_Ecu2EacSts_Eac_Active" 3 "EPAS_Ecu2EacSts_Eac_Fault" 7 "EPAS_Ecu2EacSts_Sna" ;
VAL_ 864 EPAS_Ecu2PowerMode 0 "EPASS_powerMode_Drive_Off" 1 "EPASS_powerMode_Drive_On" 2 "EPASS_powerMode_Shutdown" 3 "EPASS_powerMode_Sna" ;
VAL_ 864 EPASS_Ecu2Role 0 "EPASS_Ecu2Role_Master" 1 "EPASS_Ecu2Role_Slave" 2 "EPASS_Ecu2Role_Reserved" ;
VAL_ 864 EPASS_Ecu2State 0 "EPASS_Ecu2State_Initialisation_Arbitration" 1 "EPASS_Ecu2State_Reserved" 2 "EPASS_Ecu2State_Reserved1" 3 "EPASS_Ecu2State_Initialisation_Complete" 4 "EPASS_Ecu2State_Passive" 5 "EPASS_Ecu2State_Passive_Faulted" 6 "EPASS_Ecu2State_Assist_Active" 7 "EPASS_Ecu2State_Assist_Standby" 8 "EPASS_Ecu2State_Eac_Active" 9 "EPASS_Ecu2State_Eac_Standby" 15 "EPASS_Ecu2State_Invalid" ;
VAL_ 258 ESP_AebActive 0 "ESP_AebActive_Inactive" 1 "ESP_AebActive_Active" ;
VAL_ 258 ESP_AebAvailable 0 "ESP_AebAvailable_Not_Available" 1 "ESP_AebAvailable_Available" ;
VAL_ 258 ESP_DbsActive 0 "ESP_DbsActive_Dbs_Inactive" 1 "ESP_DbsActive_Dbs_Active" ;
VAL_ 258 ESP_DbsAvailable 0 "ESP_DbsAvailable_NotAvailable" 1 "ESP_DbsAvailable_Available" ;
VAL_ 258 ESP_PrefillActiveFeedback 0 "ESP_PrefillActiveFeedback_Inactive" 1 "ESP_PrefillActiveFeedback_Active" ;
VAL_ 258 ESP_PrefillAvailable 0 "ESP_PrefillAvailible_NotAvailable" 1 "ESP_PrefillAvailible_Available" ;
VAL_ 258 iB_BrakePedalApplied 0 "iB_BrakePedalApplied_NotApplied" 1 "iB_BrakePedalApplied_Applied" ;
VAL_ 258 iB_BrakePedalApplied_Q 0 "iB_BrakePedalApplied_Q_No_Init_Or_Off" 1 "iB_BrakePedalApplied_Q_Applied_Normal" 2 "iB_BrakePedalApplied_Q_Applied_Faulty" ;
VAL_ 524 ESP_BrakePressure_LF_Q 0 "ESP_BRAKEPRESSURE_LF_Q_NOT_INITIALIZED" 1 "ESP_BRAKEPRESSURE_LF_Q_NORMAL" 2 "ESP_BRAKEPRESSURE_LF_Q_FAULT" ;
VAL_ 524 ESP_BrakePressure_LR_Q 0 "ESP_BRAKEPRESSURE_LR_Q_NOT_INITIALIZED" 1 "ESP_BRAKEPRESSURE_LR_Q_NORMAL" 2 "ESP_BRAKEPRESSURE_LR_Q_FAULT" ;
VAL_ 524 ESP_BrakePressure_RF_Q 0 "ESP_BRAKEPRESSURE_RF_Q_NOT_INITIALIZED" 1 "ESP_BRAKEPRESSURE_RF_Q_NORMAL" 2 "ESP_BRAKEPRESSURE_RF_Q_FAULT" ;
VAL_ 524 ESP_BrakePressure_RR_Q 0 "ESP_BRAKEPRESSURE_RR_Q_NOT_INITIALIZED" 1 "ESP_BRAKEPRESSURE_RR_Q_NORMAL" 2 "ESP_BRAKEPRESSURE_RR_Q_FAULT" ;
VAL_ 524 ESP_MasterCyl_Pressure_Q 0 "ESP_MASTERCYL_PRESSURE_Q_NOT_INITIALIZED" 1 "ESP_MASTERCYL_PRESSURE_Q_NORMAL" 2 "ESP_MASTERCYL_PRESSURE_Q_FAULT" ;
VAL_ 811 ESP_EpbAvailable 0 "ESP_EpbAvailable_Not_Available" 1 "ESP_EpbAvailable_Available" ;
VAL_ 811 ESP_EpbFunctionLamp 0 "ESP_EpbFunction_Lamp_Off" 1 "ESP_EpbFunctionLamp_Continous" 2 "ESP_EpbFunctionLamp_Blink" 3 "ESP_EpbFunctionLamp_Sna" ;
VAL_ 811 ESP_EpbServiceMode 0 "ESP_EpbServiceMode_Not_Active" 1 "ESP_EpbServiceMode_Active" ;
VAL_ 811 ESP_EpbStatus 0 "ESP_EpbStatus_Released" 1 "ESP_EpbStatus_Applied" 2 "ESP_EpbStatus_Releasing" 3 "ESP_EpbStatus_Applying" 4 "ESP_EpbStatus_Dynamic_Control" 5 "ESP_EpbStatus_Unknown" 7 "ESP_EpbStatus_Sna" ;
VAL_ 811 ESP_EpbWarningLamp 0 "ESP_EpbWarningLamp_Off" 1 "ESP_EpbWarningLamp_Continous" 2 "ESP_EpbWarningLamp_Blink" 3 "ESP_EpbWarningLamp_Sna" ;
VAL_ 520 ESP_Abs_Active 0 "ABS_ACTIVE_INACTIVE" 1 "ABS_ACTIVE_ACTIVE" ;
VAL_ 520 ESP_Abs_OffRoad_Mode 0 "ABS_OFFROAD_NORMAL" 1 "ABS_OFFROAD_OFFROAD" ;
VAL_ 520 ESP_BrakeLightActive 0 "ESP_BRAKELIGHTACTIVE_INACTIVE" 1 "ESP_BRAKELIGHTACTIVE_ACTIVE" ;
VAL_ 520 ESP_BrakeLightActive_Q 0 "ESP_BRAKELIGHTACTIVE_Q_INVALID" 1 "ESP_BRAKELIGHTACTIVE_Q_VALID" ;
VAL_ 520 ESP_Esp_Active 0 "ESP_ACTIVE_INACTIVE" 1 "ESP_ACTIVE_ACTIVE" ;
VAL_ 520 ESP_FaultLamp_ABS 0 "ESP_FAULTLAMP_ABS_OFF" 1 "ESP_FAULTLAMP_ABS_ON" ;
VAL_ 520 ESP_FaultLamp_EBD 0 "ESP_FAULTLAMP_EBD_OFF" 1 "ESP_FAULTLAMP_EBD_ON" ;
VAL_ 520 ESP_FaultLamp_VDC 0 "ESP_FAULTLAMP_VDC_OFF" 1 "ESP_FAULTLAMP_VDC_ON" ;
VAL_ 520 ESP_Hba_Active 0 "ESP_HBAACTV_INACTIVE" 1 "ESP_HBAACTV_ACTIVE" ;
VAL_ 520 ESP_Hhc_Active 0 "ESP_HHCACTV_INACTIVE" 1 "ESP_HHCACTV_ACTIVE" ;
VAL_ 520 ESP_Hhc_Available 0 "ESP_HHCAVL_NOT_INITIALIZED" 1 "ESP_HHCAVL_ACTIVE" ;
VAL_ 520 ESP_Lfc_Active 0 "LFC_ACTIVE_INACTIVE" 1 "LFC_ACTIVE_ACTIVE" ;
VAL_ 520 ESP_Lfc_Available 0 "LFC_AVAILABLE_NOT_AVAILABLE" 1 "LFC_AVAILABLE_AVAILABLE" ;
VAL_ 520 ESP_Partial_Mode 0 "ESP_PATA_MODE_NORMAL" 1 "ESP_PATA_MODE_SPORT" 2 "ESP_PATA_MODE_ESC_OFF" 3 "ESP_PATA_MODE_RESERVED" ;
VAL_ 520 ESP_Tsm_Active 0 "TSM_ACTIVE_INACTIVE" 1 "TSM_ACTIVE_ACTIVE" ;
VAL_ 520 ESP_Vehicle_Speed_Q 0 "ESP_VEHICLE_SPEED_Q_NOT_INITIALIZED" 1 "ESP_VEHICLE_SPEED_Q_NORMAL" 2 "ESP_VEHICLE_SPEED_Q_FAULT" ;
VAL_ 432 ESP_Torque_Front_MaxQ 0 "ESP_TorqueFront_MaxQ_Invalid" 1 "ESP_TorqueFront_MaxQ_Valid" ;
VAL_ 432 ESP_Torque_Front_MinQ 0 "ESP_TorqueFront_MinQ_Invalid" 1 "ESP_TorqueFront_MinQ_Valid" ;
VAL_ 448 ESP_Torque_Rear_MaxQ 0 "ESP_TorqueLimitRear_MaxQ_Invalid" 1 "ESP_TorqueLimitRear_MaxQ_Valid" ;
VAL_ 448 ESP_Torque_Rear_MinQ 0 "ESP_TorqueLimitRear_MinQ_Invalid" 1 "ESP_TorqueLimitRear_MinQ_Valid" ;
VAL_ 523 ESP_Wheel_Pulse_Left_Front_Q 0 "ESP_WHEEL_PULSE_LEFT_FRONT_Q_NOT_INITIALIZED" 1 "ESP_WHEEL_PULSE_LEFT_FRONT_Q_NORMAL" 2 "ESP_WHEEL_PULSE_LEFT_FRONT_Q_FAULT" ;
VAL_ 523 ESP_Wheel_Pulse_Left_Rear_Q 0 "ESP_WHEEL_PULSE_LEFT_REAR_Q_NOT_INITIALIZED" 1 "ESP_WHEEL_PULSE_LEFT_REAR_Q_NORMAL" 2 "ESP_WHEEL_PULSE_LEFT_REAR_Q_FAULT" ;
VAL_ 523 ESP_Wheel_Pulse_Right_Front_Q 0 "ESP_WHEEL_PULSE_RIGHT_FRONT_Q_NOT_INITIALIZED" 1 "ESP_WHEEL_PULSE_RIGHT_FRONT_Q_NORMAL" 2 "ESP_WHEEL_PULSE_RIGHT_FRONT_Q_FAULT" ;
VAL_ 523 ESP_Wheel_Pulse_Right_Rear_Q 0 "ESP_WHEEL_PULSE_RIGHT_REAR_Q_NOT_INITIALIZED" 1 "ESP_WHEEL_PULSE_RIGHT_REAR_Q_NORMAL" 2 "ESP_WHEEL_PULSE_RIGHT_REAR_Q_FAULT" ;
VAL_ 521 ESP_Wheel_Dir_Left_Front 0 "ESP_WHEEL_DIR_LEFT_FRONT_FORWARDDIRECTION" 1 "ESP_WHEEL_DIR_LEFT_FRONT_BACKWARDDIRECTION" 2 "ESP_WHEEL_DIR_LEFT_FRONT_STANDSTILL" 3 "ESP_WHEEL_DIR_LEFT_FRONT_NOTDEFINABLE" ;
VAL_ 521 ESP_Wheel_Dir_Right_Front 0 "ESP_WHEEL_DIR_RIGHT_FRONT_FORWARDDIRECTION" 1 "ESP_WHEEL_DIR_RIGHT_FRONT_BACKWARDDIRECTION" 2 "ESP_WHEEL_DIR_RIGHT_FRONT_STANDSTILL" 3 "ESP_WHEEL_DIR_RIGHT_FRONT_NOTDEFINABLE" ;
VAL_ 521 ESP_Wheel_Speed_Left_Front_Q 0 "ESP_WHEEL_SPEED_LEFT_FRONT_Q_NOT_INITIALIZED" 1 "ESP_WHEEL_SPEED_LEFT_FRONT_Q_NORMAL" 2 "ESP_WHEEL_SPEED_LEFT_FRONT_Q_FAULT" ;
VAL_ 521 ESP_Wheel_Speed_Right_Front_Q 0 "ESP_WHEEL_SPEED_RIGHT_FRONT_Q_NOT_INITIALIZED" 1 "ESP_WHEEL_SPEED_RIGHT_FRONT_Q_NORMAL" 2 "ESP_WHEEL_SPEED_RIGHT_FRONT_Q_FAULT" ;
VAL_ 522 ESP_Wheel_Dir_Left_Rear 0 "ESP_WHEEL_DIR_LEFT_REAR_FORWARDDIRECTION" 1 "ESP_WHEEL_DIR_LEFT_REAR_BACKWARDDIRECTION" 2 "ESP_WHEEL_DIR_LEFT_REAR_STANDSTILL" 3 "ESP_WHEEL_DIR_LEFT_REAR_NOTDEFINABLE" ;
VAL_ 522 ESP_Wheel_Dir_Right_Rear 0 "ESP_WHEEL_DIR_RIGHT_REAR_FORWARDDIRECTION" 1 "ESP_WHEEL_DIR_RIGHT_REAR_BACKWARDDIRECTION" 2 "ESP_WHEEL_DIR_RIGHT_REAR_STANDSTILL" 3 "ESP_WHEEL_DIR_RIGHT_REAR_NOTDEFINABLE" ;
VAL_ 522 ESP_Wheel_Speed_Left_Rear_Q 0 "ESP_WHEEL_SPEED_LEFT_REAR_Q_NOT_INITIALIZED" 1 "ESP_WHEEL_SPEED_LEFT_REAR_Q_NORMAL" 2 "ESP_WHEEL_SPEED_LEFT_REAR_Q_FAULT" ;
VAL_ 522 ESP_Wheel_Speed_Right_Rear_Q 0 "ESP_WHEEL_SPEED_RIGHT_REAR_Q_NOT_INITIALIZED" 1 "ESP_WHEEL_SPEED_RIGHT_REAR_Q_NORMAL" 2 "ESP_WHEEL_SPEED_RIGHT_REAR_Q_FAULT" ;
VAL_ 907 ESPiB1_IgnitionOn 0 "ESPIB1_IgnitionOn_Not_Initilized" 1 "ESPIB1_IgnitionOn_Normal" ;
VAL_ 907 ESPiB1_VehicleSpeed_Q 0 "ESPiB1_VehicleSpeed_Q_VehicleSpeedQualifier_NotInit" 1 "ESPiB1_VehicleSpeed_Q_VehicleSpeedQualifier_Normal" 2 "ESPiB1_VehicleSpeed_Q_VehicleSpeedQualifier_Faulty" ;
VAL_ 908 ESPiB2_qTargetExternal_Q 0 "ESPiB2_qTargetExternal_Q_QTarget_Off" 1 "ESPiB2_qTargetExternal_Q_QTarget_EBR" 2 "ESPiB2_qTargetExternal_Q_QTarget_EBRmaxPerformance" ;
VAL_ 909 ESPiB3_ABSActive 0 "ESPIB3_ABSACTIVE_ABS_IS_INACTIVE" 1 "ESPIB3_ABSACTIVE_ABS_IS_ACTIVE" ;
VAL_ 909 ESPiB3_ForceBlendingActive 0 "ESPIB3_FORCEBLENDINGACTIVE_PFC_INACTIVE" 1 "ESPIB3_FORCEBLENDINGACTIVE_PFC_HOLD" 2 "ESPIB3_FORCEBLENDINGACTIVE_PFC_ACTIVE" ;
VAL_ 909 ESPiB3_pForceBlendingMC_Q 0 "ESPIB3_PFORCEBLENDINGMC_Q_PFORCEBLENDINGMC_NOTINITIALIZED" 1 "ESPIB3_PFORCEBLENDINGMC_Q_PFORCEBLENDINGMC_NORMAL" 2 "ESPIB3_PFORCEBLENDINGMC_Q_PFORCEBLENDINGMC_FAULTY" ;
VAL_ 909 ESPiB3_pMC1_Q 0 "ESPIB3_PMC1_Q_MCPRESSUREQUALIFIER_NOTINIT" 1 "ESPIB3_PMC1_Q_MCPRESSUREQUALIFIER_NORMAL" 2 "ESPIB3_PMC1_Q_MCPRESSUREQUALIFIER_FAULTY" ;
VAL_ 909 ESPiB3_pMcVirtual_Q 0 "ESPIB3_PMCVIRTUAL_Q_PMCVIRTUAL_NOTINITIALIZED" 1 "ESPIB3_PMCVIRTUAL_Q_PMCVIRTUAL_NORMAL" 2 "ESPIB3_PMCVIRTUAL_Q_PMCVIRTUAL_FAULTY" ;
VAL_ 910 iBESP1_ExtReqStatus 0 "iBESP1_ExtReqStatus_NotInitialized" 1 "iBESP1_ExtReqStatus_EBR_NotAvailable" 2 "iBESP1_ExtReqStatus_EBR_Available" ;
VAL_ 910 iBESP1_sOutputRodAct_Q 0 "IBESP1_SOUTPUTRODACT_Q_SOUTPUTRODACT_NOTINITIALIZED" 1 "IBESP1_SOUTPUTRODACT_Q_SOUTPUTRODACT_NORMAL" 2 "IBESP1_SOUTPUTRODACT_Q_SOUTPUTRODACT_FAULTY" ;
VAL_ 910 iBESP1_sOutputRodDriver_Q 0 "IBESP1_SOUTPUTRODDRIVER_Q_SOUTPUTRODDRIVER_NOTINITIALIZED" 1 "IBESP1_SOUTPUTRODDRIVER_Q_SOUTPUTRODDRIVER_NORMAL" 2 "IBESP1_SOUTPUTRODDRIVER_Q_SOUTPUTRODDRIVER_FAULTY" ;
VAL_ 911 iBESP2_BrakePedalApplied 0 "iBESP2_BrakePedalApplied_NotApplied" 1 "iBESP2_BrakePedalApplied_Applied" ;
VAL_ 911 iBESP2_BrakePedalApplied_Q 0 "IBESP2_BRAKEPEDALAPPLIED_Q_BRAKE_PEDAL_APPLIED_NO_INIT_OR_OFF" 1 "IBESP2_BRAKEPEDALAPPLIED_Q_BRAKE_PEDAL_APPLIED_NORMAL" 2 "IBESP2_BRAKEPEDALAPPLIED_Q_BRAKE_PEDAL_APPLIED_FAULTY" ;
VAL_ 911 iBESP2_pRunout_Q 0 "IBESP2_PRUNOUT_Q_P_RUNOUT_NOT_INITIALIZED" 1 "IBESP2_PRUNOUT_Q_P_RUNOUT_NORMAL" 2 "IBESP2_PRUNOUT_Q_P_RUNOUT_FAULTY" ;
VAL_ 911 iBESP2_RprMode 0 "IBESP2_RPRMODE_RPR_PASSIVE" 1 "IBESP2_RPRMODE_RPR_PRELOAD" 2 "IBESP2_RPRMODE_RPR_HOLD" 3 "IBESP2_RPRMODE_RPR_SUCTION" 4 "IBESP2_RPRMODE_RPR_HOLDLOWPRESSURE" 5 "IBESP2_RPRMODE_RPR_ABORT" ;
VAL_ 1640 OCS_FrontPassClass 0 "OCS_FrontPassClass_Classification_Unknown" 1 "OCS_FrontPassClass_Reserved_1" 2 "OCS_FrontPassClass_One_YO_CRS" 3 "OCS_FrontPassClass_Reserved_2" 4 "OCS_FrontPassClass_Reserved_3" 5 "OCS_FrontPassClass_Reserved_4" 6 "OCS_FrontPassClass_Small_Adult" 7 "OCS_FrontPassClass_Medium_Adult" 8 "OCS_FrontPassClass_Reserved_5" 9 "OCS_FrontPassClass_Reserved_6" 10 "OCS_FrontPassClass_Reserved_7" 11 "OCS_FrontPassClass_Reserved_8" 12 "OCS_FrontPassClass_Reserved_9" 13 "OCS_FrontPassClass_Reserved_10" 14 "OCS_FrontPassClass_Reserved_11" 15 "OCS_FrontPassClass_Reserved_12" ;
VAL_ 1640 OCS_FrontPassClassValid 0 "Not_Valid" 1 "Valid" ;
VAL_ 1640 OCS_FrontPassFaultStatus 0 "No_Fault_Present" 1 "Fault_Status" 2 "Reserved_1" 3 "Reserved_2" ;
VAL_ 1640 OCS_FrontPassSBRStatus 0 "Unknown" 1 "Empty" 2 "Occupied" ;
VAL_ 1640 OCS_OperatingMode 0 "OCS_OperatingMode_Initialisation" 1 "OCS_OperatingMode_Normal_Mode" 2 "OCS_OperatingMode_Empty_Seat_Calibration_Active" 3 "OCS_OperatingMode_Barrier_Airbag_Test_Mode" 4 "OCS_OperatingMode_Voltage_Out_Of_Range" 5 "OCS_OperatingMode_Falut_Active" 6 "OCS_OperatingMode_Reserved_1" 7 "OCS_OperatingMode_Reserved_2" 8 "OCS_OperatingMode_Reserved_3" 9 "OCS_OperatingMode_Reserved_4" 10 "OCS_OperatingMode_Reserved_5" 11 "OCS_OperatingMode_Reserved_6" 12 "OCS_OperatingMode_Reserved_7" 13 "OCS_OperatingMode_Reserved_8" 14 "OCS_OperatingMode_Reserved_9" 15 "OCS_OperatingMode_Reserved_10" ;
VAL_ 1640 OCS_Reserved_1 0 "OCS_Reserved_Reserved" ;
VAL_ 1640 OCS_Reserved_2 0 "OCS_Reserved_2_Reserved" ;
VAL_ 516 RCM_ALR_Status_Signal 0 "ALR_Unknown" 1 "ALR_Not_Engaged" 2 "ALR_Engaged" 3 "ALR_Invalid" ;
VAL_ 309 RCM_IMU_Heave_Stat_Fail 0 "RCM_IMU_Heave_Stat_Fail_NotFailed" 1 "RCM_IMU_Heave_Stat_Fail_Failed" ;
VAL_ 309 RCM_IMU_Heave_Stat_Init 0 "RCM_IMU_Heave_Stat_Init_Finished" 1 "RCM_IMU_Heave_Stat_Init_Running" ;
VAL_ 309 RCM_IMU_Heave_Stat_SensAvail 0 "RCM_IMU_Heave_Stat_SensAvail_InSpec" 1 "RCM_IMU_Heave_Stat_SensAvail_NotInSpec" ;
VAL_ 309 RCM_IMU_Heave_Stat_Startup 0 "RCM_IMU_Heave_Stat_Startup_Finished" 1 "RCM_IMU_Heave_Stat_Startup_Running" ;
VAL_ 309 RCM_IMU_Roll_Stat_Fail 0 "RCM_IMU_Roll_Stat_Fail_NotFailed" 1 "RCM_IMU_Roll_Stat_Fail_Failed" ;
VAL_ 309 RCM_IMU_Roll_Stat_Init 0 "RCM_IMU_Roll_Stat_Init_Finished" 1 "RCM_IMU_Roll_Stat_Init_Running" ;
VAL_ 309 RCM_IMU_Roll_Stat_SensAvail 0 "RCM_IMU_Roll_Stat_SensAvail_InSpec" 1 "RCM_IMU_Roll_Stat_SensAvail_NotInSpec" ;
VAL_ 309 RCM_IMU_Roll_Stat_Startup 0 "RCM_IMU_Roll_Stat_Startup_Finished" 1 "RCM_IMU_Roll_Stat_Startup_Running" ;
VAL_ 304 RCM_IMU_LatAcc_Stat_Fail 0 "RCM_IMU_LatAcc_Stat_Fail_NotFailed" 1 "RCM_IMU_LatAcc_Stat_Fail_Failed" ;
VAL_ 304 RCM_IMU_LatAcc_Stat_Init 0 "RCM_IMU_LatAcc_Stat_Init_Finished" 1 "RCM_IMU_LatAcc_Stat_Init_Running" ;
VAL_ 304 RCM_IMU_LatAcc_Stat_SensAvail 0 "RCM_IMU_LatAcc_Stat_SensAvail_InSpec" 1 "RCM_IMU_LatAcc_Stat_SensAvail_NotInSpec" ;
VAL_ 304 RCM_IMU_LatAcc_Stat_Startup 0 "RCM_IMU_LatAcc_Stat_Startup_Finished" 1 "RCM_IMU_LatAcc_Stat_Startup_Running" ;
VAL_ 304 RCM_IMU_Yaw_Stat_Fail 0 "RCM_IMU_Yaw_Stat_Fail_NotFailed" 1 "RCM_IMU_Yaw_Stat_Fail_Failed" ;
VAL_ 304 RCM_IMU_Yaw_Stat_Init 0 "RCM_IMU_Yaw_Stat_Init_Finish" 1 "RCM_IMU_Yaw_Stat_Init_Running" ;
VAL_ 304 RCM_IMU_Yaw_Stat_SensAvail 0 "RCM_IMU_Yaw_Stat_SensAvail_InSpec" 1 "RCM_IMU_Yaw_Stat_SensAvail_NotInSpec" ;
VAL_ 304 RCM_IMU_Yaw_Stat_Startup 0 "RCM_IMU_Yaw_Stat_Startup_Finished" 1 "RCM_IMU_Yaw_Stat_Startup_Running" ;
VAL_ 320 RCM_IMU_LongAcc_Stat_Fail 0 "RCM_IMU_LongAcc_Stat_Fail_NotFailed" 1 "RCM_IMU_LongAcc_Stat_Fail_Failed" ;
VAL_ 320 RCM_IMU_LongAcc_Stat_Init 0 "RCM_IMU_LongAcc_Stat_Init_Finished" 1 "RCM_IMU_LongAcc_Stat_Init_Running" ;
VAL_ 320 RCM_IMU_LongAcc_Stat_SensAvail 0 "RCM_IMU_LongAcc_Stat_SensAvail_InSpec" 1 "RCM_IMU_LongAcc_Stat_SensAvail_NotInSpec" ;
VAL_ 320 RCM_IMU_LongAcc_Stat_Startup 0 "RCM_IMU_LongAcc_Stat_Startup_Finished" 1 "RCM_IMU_LongAcc_Stat_Startup_Running" ;
VAL_ 826 RCM_Status_DETECT_CRUSH 0 "DETECT_CRUSH_Normal_Condition" 1 "DETECT_CRUSH_Collision_Detection" ;
VAL_ 826 RCM_Status_IND_ACT_RCM_PASS 0 "IWBP_On_Ind_onOFF_Ind_on" 1 "IWBP_On_Ind_offOFF_Ind_on" 2 "IWBP_On_Ind_onOFF_Ind_off" 3 "IWBP_On_Ind_offOFF_Ind_off" ;
VAL_ 826 RCM_Status_IND_WARN_BELT_DRIVER 0 "IWBP_Equipped" 1 "IWBP_Not_Equipped" 2 "IWBP_Undetermined" 3 "IWBP_SW_Failure" ;
VAL_ 826 RCM_Status_IND_WARN_BELT_PASS 0 "IWBP_Equipped" 1 "IWBP_Not_Equipped" 2 "IWBP_Undetermined" 3 "IWBP_SW_Failure" ;
VAL_ 826 RCM_Status_IND_WARN_RCM 0 "IND_WARN_RCM_Off" 1 "IND_WARN_RCM_Lighting" ;
VAL_ 64 SAS_Status_Calibrated 0 "SAS_Status_Calibrated_Not_Calibrated" 1 "SAS_Status_Calibrated_Calibrated" ;
VAL_ 64 SAS_StatusQ 0 "SAS_Status_UndefinedDataACCur" 1 "SAS_Status_TmpUnDefinedData" 2 "SAS_Status_DataACCurrentNotWithinSpecification" 3 "SAS_Status_ACCurrentData" ;
VAL_ 357 VDM_AdasStalkAccCancelRes 0 "VDM_AdasStalkAccCancelRes_NoRequired" 1 "VDM_AdasStalkAccCancelRes_Cancel" 2 "VDM_AdasStalkAccCancelRes_Resume" ;
VAL_ 357 VDM_AdasStalkAccEnableAdj 0 "VDM_AdasStalkAccEnableAdj_No_Required" 1 "VDM_AdasStalkAccEnableAdj_UpDetent1" 2 "VDM_AdasStalkAccEnableAdj_UpDetent2" 3 "VDM_AdasStalkAccEnableAdj_DownDetent1" 4 "VDM_AdasStalkAccEnableAdj_DownDetent2" ;
VAL_ 357 VDM_AdasStalkAutonomyButton 0 "VDM_AdasStalkAutonomyButton_No_Required" 1 "VDM_AdasStalkAutonomyButton_Pressed" ;
VAL_ 357 VDM_AdasStalkGapAdjust 0 "VDM_AdasStalkGapAdjust_No_Required" 1 "VDM_AdasStalkGapAdjust_GapDecrement" 2 "VDM_AdasStalkGapAdjust_GapIncrement" ;
VAL_ 354 VDM_AdasAccelRequestAcknowledged 0 "VDM_AdasAccelRequestAcknowledged_Not_Acknowledged" 1 "VDM_AdasAccelRequestAcknowledged_Acknowledged" 2 "VDM_AdasAccelRequestAcknowledged_Fault_Ignored" 3 "VDM_AdasAccelRequestAcknowledged_Sna" ;
VAL_ 354 VDM_AdasDriverAccelPriorityStatu 0 "VDM_AdasDriverAccelPriorityStatus_Driver" 1 "VDM_AdasDriverAccelPriorityStatus_Adas" ;
VAL_ 354 VDM_AdasDriverModeStatus 0 "VDM_AdasDriverModeStatus_Human" 1 "VDM_AdasDriverModeStatus_Adas" 2 "VDM_AdasDriverModeStatus_Reserved" 3 "VDM_AdasDriverModeStatus_Sna" ;
VAL_ 354 VDM_AdasFaultStatus 0 "VDM_AdasFlaultStatus_No_Fault" 1 "VDM_AdasFaultStatus_Brk_Intv" 2 "VDM_AdasFlaultStatus_Cntr_Fault" 3 "VDM_AdasFlaultStatus_Imps_Cmd" 15 "VDM_AdasFlaultStatus_Sna" ;
VAL_ 354 VDM_AdasInterfaceStatus 0 "VDM_AdasInterfaceStatus_Unavailable" 1 "VDM_AdasInterfaceStatus_Available" 2 "VDM_AdasInterfaceStatus_Enabled" 3 "VDM_AdasInterfaceStatus_Faulted" ;
VAL_ 354 VDM_AdasVehicleHoldStatus 0 "VDM_AdasVehicleHoldStatus_NotHold" 1 "VDM_AdasVehicleHoldStatus_Hold" ;
VAL_ 384 CGM_DriverPresent 0 "CGM_DriverPresent_Driver_Not_Present" 1 "CGM_DriverPresent_Driver_Present" 3 "CGM_DriverPresent_Invalid" ;
VAL_ 384 CGM_IgnSwtState 0 "IGNSWTSTATE_OFF" 1 "IGNSWTSTATE_STANDBY" 2 "IGNSWTSTATE_ACCESSORY" 3 "IGNSWTSTATE_RUN" 4 "IGNSWTSTATE_CRANK" ;
VAL_ 384 CGM_TrailerPresent 0 "CGM_TrailerPresent_Trailer_Not_Present" 1 "CGM_TrailerPresent_Trailer_Present" 3 "CGM_TrailerPresent_Invalid" ;
VAL_ 929 VDM_AchDriveMode 0 "VDM_AchDriveMode_Eco" 1 "VDM_AchDriveMode_OnRoadComford" 2 "VDM_AchDriveMode_OnRoadSport" 3 "VDM_AchDriveMode_OffRoad" 4 "VDM_AchDriveMode_OffRoadSport" 5 "VDM_AchDriveMode_Autonomy" ;
VAL_ 929 VDM_AchDriveMode4x4 0 "VDM_AchDriveMode4x4_A4x4Auto" 1 "VDM_AchDriveMode4x4_P4x4Permenant" 6 "VDM_AchDriveMode4x4_I_Transition" 7 "VDM_AchDriveMode4x4_Fault" ;
VAL_ 929 VDM_AchDriveModeAbs 0 "VDM_AchDriveModeAbs_OnRoad" 1 "VDM_AchDriveModeAbs_OffRoad" 6 "VDM_AchDriveModeAbs_InTransition" 7 "VDM_AchDriveModeAbs_Fault" ;
VAL_ 929 VDM_AchDriveModeAirSuspension 0 "VDM_AchDriveModeAirSuspension_Kneel" 1 "VDM_AchDriveModeAirSuspension_Aero" 2 "VDM_AchDriveModeAirSuspension_Design" 3 "VDM_AchDriveModeAirSuspension_High" 4 "VDM_AchDriveModeAirSuspension_Max" 7 "VDM_AchDriveModeAirSuspension_Null" ;
VAL_ 929 VDM_AchDriveModeDamping 0 "VDM_AchDriveModeDamping_Kneel" 1 "VDM_AchDriveModeDamping_Aero" 2 "VDM_AchDriveModeDamping_Design" 3 "VDM_AchDriveModeDamping_High" 4 "VDM_AchDriveModeDamping_AirSuspensionMax" 6 "VDM_AchDriveModeDamping_InTransition" 7 "VDM_AchDriveModeDamping_Fault" ;
VAL_ 929 VDM_AchDriveModeDrivability 0 "VDM_AchDriveModeDrivability_Eco" 1 "VDM_AchDriveModeDrivability_Sport" 2 "VDM_AchDriveModeDrivability_OffRoad" 6 "VDM_AchDriveModeDrivability_InTransition" 7 "VDM_AchDriveModeDrivability_Null" ;
VAL_ 929 VDM_AchDriveModeEpas 0 "VDM_AchDriveModeEpas_TcsStable" 1 "VDM_AchDriveModeEpas_TcsSportRoad" 2 "VDM_AchDriveModeEpas_TcsSportOffRoad" 3 "VDM_AchDriveModeEpas_TcsOff" 7 "VDM_AchDriveModeEpas_Null" ;
VAL_ 929 VDM_AchDriveModeEsp 0 "VDM_AchDriveModeEsp_EspOn" 1 "VDM_AchDriveModeEsp_EspReduced" 2 "VDM_AchDriveModeEsp_EspOff" 6 "VDM_AchDriveModeEsp_InTransition" 7 "VDM_AchDriveModeEsp_Null" ;
VAL_ 929 VDM_AchDriveModeRequestConfirm 0 "VDM_AchDriveModeRequestConfirm_NoRequest" 1 "VDM_AchDriveModeRequestConfirm_Request" ;
VAL_ 929 VDM_AchDriveModeRequestPullRearw 0 "VDM_AchDriveModeRequestPullRearward_NoRequired" 1 "VDM_AchDriveModeRequestPullRearward_Required" ;
VAL_ 929 VDM_AchDriveModeRequestPushDown 0 "VDM_AchDriveModeRequestPushDown_NoRequired" 1 "VDM_AchDriveModeRequestPushDown_Required" ;
VAL_ 929 VDM_AchDriveModeRequestPushForwa 0 "VDM_AchDriveModeRequestPushForward_NoRequired" 1 "VDM_AchDriveModeRequestPushForward_Required" ;
VAL_ 929 VDM_AchDriveModeRequestPushUp 0 "VDM_AchDriveModeRequestPushUp_NoRequired" 1 "VDM_AchDriveModeRequestPushUp_Required" ;
VAL_ 929 VDM_AchDriveModeRequestRest 0 "VDM_AchDriveModeRequestRest_NoRequired" 1 "VDM_AchDriveModeRequestRest_Required" ;
VAL_ 929 VDM_AchDriveModeRollControl 0 "VDM_AchDriveModeRollControl_Low" 1 "VDM_AchDriveModeRollControl_Middle" 2 "VDM_AchDriveModeRollControl_High" 6 "VDM_AchDriveModeRollControl_InTransition" 7 "VDM_AchDriveModeRollControl_Null" ;
VAL_ 929 VDM_AchDriveModeTcs 0 "VDM_AchDriveModeTcs_Stable" 1 "VDM_AchDriveModeTcs_SportRoad" 2 "VDM_AchDriveModeTcs_SportOffRoad" 3 "VDM_AchDriveModeTcs_Off" 7 "VDM_AchDriveModeTcs_Null" ;
VAL_ 338 VDM_ABSOffRoadModeRequest 0 "VDM_ABSOffRoadModeRequest_Inactive" 1 "VDM_ABSOffRoadModeRequest_Active" ;
VAL_ 338 VDM_EpasPowerMode 0 "VDM_EpasPowerMode_Drive_Off" 1 "VDM_EpasPowerMode_Drive_On" 2 "VDM_EpasPowerMode_Shutdown" ;
VAL_ 338 VDM_EpbRequest 0 "VDM_EpbRequest_No_Request" 1 "VDM_EpbRequest_Release_Req" 2 "VDM_EpbRequest_Apply_Req" 3 "VDM_EpbRequest_Sna" ;
VAL_ 338 VDM_EspPartialModeRequest 0 "VDM_EspPartialModeRequest_Normal" 1 "VDM_EspPartialModeRequest_Sport" 2 "VDM_EspPartialModeRequest_Esc_Off" 3 "VDM_EspPartialModeRequest_Reserved" ;
VAL_ 338 VDM_HhcActiveRequest 0 "VDM_HhcActiveRequest_Inactive" 1 "VDM_HhcActiveRequest_Active" ;
VAL_ 338 VDM_LfcActiveRequest 0 "VDM_LfcActiveRequest_Inactive" 1 "VDM_LfcActiveRequest_Active" ;
VAL_ 338 VDM_LfcRequestType 0 "LFC_Request_Type_No_Request" 1 "LFC_Request_Type_Brake_Torque_Request_Fx" 2 "LFC_Request_Type_Standstill_Hold_Request_Ssm" 3 "LFC_Request_Type_Release_Ssm" ;
VAL_ 338 VDM_StcActiveRequest 0 "Stc_NotActive" 1 "Stc_Active" ;
VAL_ 338 VDM_StcFault 0 "Stc_NoFault" 1 "Stc_Fault" ;
VAL_ 338 VDM_SteeringModeRequest 0 "VDM_SteeringModeRequest_Default" 1 "VDM_SteeringModeRequest_Normal" 2 "VDM_SteeringModeRequest_Sport" 3 "VDM_SteeringModeRequest_Comfort" ;
VAL_ 336 VDM_Prndl_Request 0 "VDM_Prndl_Request_No_Req" 1 "VDM_Prndl_Request_Park" 2 "VDM_Prndl_Request_Reverse" 3 "VDM_Prndl_Request_Neutral" 4 "VDM_Prndl_Request_Drive" ;
VAL_ 336 VDM_Prndl_Status 0 "VDM_Prndl_Status_Not_Defined" 1 "VDM_Prndl_Status_Park" 2 "VDM_Prndl_Status_Reverse" 3 "VDM_Prndl_Status_Neutral" 4 "VDM_Prndl_Status_Drive" ;
VAL_ 336 VDM_PropsnActv 0 "VDM_PropsnActv_Not_Defined" 1 "VDM_PropsnActv_Active" 2 "VDM_PropsnActv_Inactive" ;
VAL_ 336 VDM_VehicleSpeedQ 0 "VDM_VehSpdQ_Inactive" 1 "VDM_VehSpdQ_Active" ;
VAL_ 529 VDM_OutputTorqueFrontQ 0 "VDM_OutputTorqueFrontQ_Invalid" 1 "VDM_OutputTorqueFrontQ_Valid" ;
VAL_ 529 VDM_Torque_Front_MaxQ 0 "VDM_Torque_Front_MaxQ_Invalid" 1 "VDM_Torque_Front_MaxQ_Valid" ;
VAL_ 529 VDM_Torque_Front_MinQ 0 "VDM_Torque_Front_MinQ_Invalid" 1 "VDM_Torque_FrontinQ_Valid" ;
VAL_ 530 VDM_OutputTorqueRearQ 0 "VDM_OutputTorqueRearQ_Invalid" 1 "VDM_OutputTorqueRearQ_Valid" ;
VAL_ 530 VDM_Torque_Rear_MaxQ 0 "VDM_Torque_Rear_MaxQ_Invalid" 1 "VDM_Torque_Rear_MaxQ_Valid" ;
VAL_ 530 VDM_Torque_Rear_MinQ 0 "VDM_Torque_Rear_MinQ_Invalid" 1 "VDM_Torque_Rear_MinQ_Valid" ;
VAL_ 1024 VCM_BatterySize 0 "VCM_BatterySize_Sna" 1 "VCM_BatterySize_A105kW" 2 "VCM_BatterySize_A130kW" 3 "VCM_BatterySize_A180kW" 4 "VCM_BatterySize_BxxxkW" 5 "VCM_BatterySize_CxxxkW" 6 "VCM_BatterySize_DxxxkW" 7 "VCM_BatterySize_ExxxkW" ;
VAL_ 1024 VCM_HandOfDrive 0 "VCM_HandOfDrive_Lhd" 1 "VCM_HandOfDrive_Rhd" ;
VAL_ 1024 VCM_Market 0 "VCM_Market_Sna" 1 "VCM_Market_RegionB" 2 "VCM_Market_RegionC" 3 "VCM_Market_RegionD" 4 "VCM_Market_RegionE" 5 "VCM_Market_RegionF" 6 "VCM_Market_RegionG" 7 "VCM_Market_RegionH" ;
VAL_ 1024 VCM_VehicleType 0 "VCM_VehicleType_Sna" 1 "VCM_VehicleType_R1T" 2 "VCM_VehicleType_R1S" 3 "VCM_VehicleType_Reserved_AProj" 4 "VCM_VehicleType_Reserved_BProj" 5 "VCM_VehicleType_Reserved_CProj" 6 "VCM_VehicleType_Reserved_DProj" 7 "VCM_VehicleType_Reserved_EProj" ;
SIG_GROUP_ 257 ACM_AebRequest 1 : ACM_AebRequest_Checksum ACM_AebRequest_Counter ACM_DbsLevel ACM_DecelRequest ACM_EnableRequest ACM_FailInfo ACM_OnOffStatus ACM_PrefillEnableRequest ACM_StopRequest ACM_WarnLevel;
SIG_GROUP_ 288 ACM_lkaHbaCmd 1 : ACM_FailinfoAeb ACM_HapticRequest ACM_hbaLamp ACM_hbaOpt ACM_hbaSysState ACM_lkaActToi ACM_lkaHandsoffDisplayWarning ACM_lkaHandsoffSoundWarning ACM_lkaHbaCmd_Checksum ACM_lkaHbaCmd_Counter ACM_lkaLaneRecogState ACM_lkaLHWarning ACM_lkaRHWarning ACM_lkaStrToqReq ACM_lkaSymbolState ACM_lkaToiFlt;
SIG_GROUP_ 352 ACM_longitudinalRequest 1 : ACM_AccelerationRequest ACM_AccelerationRequestType ACM_longInterfaceEnable ACM_longitudinalRequest_Checksum ACM_longitudinalRequest_Counter ACM_PrndRequired ACM_VehicleHoldRequired;
SIG_GROUP_ 256 ACM_Status 1 : ACM_FaultStatus ACM_FeatureStatus ACM_Status_Checksum ACM_Status_Counter;
SIG_GROUP_ 272 ACM_SteeringControl 1 : ACM_EacEnabled ACM_HapticRequired ACM_SteeringAngleRequest ACM_SteeringControl_Checksum ACM_SteeringControl_Counter;
SIG_GROUP_ 880 ACM_tsrCmd 1 : ACM_tsrAddInfoDisplay ACM_tsrCmd_Checksum ACM_tsrCmd_Counter ACM_tsrConInfoStaCon1 ACM_tsrConInfoStaCon2 ACM_tsrOvrlapSignDis ACM_tsrSpdDisClsMain ACM_tsrSpdDisCluCon1 ACM_tsrSpdDisCluCon2 ACM_tsrSpdDisCluConM ACM_tsrStatus;
SIG_GROUP_ 912 EPAS_AdasStatus 1 : EPAS_AdasStatus_Checksum EPAS_AdasStatus_Counter EPAS_EacErrorCode EPAS_EacStatus EPAS_InternalSas EPAS_InternalSasQ EPAS_SteeringAngleSpeed;
SIG_GROUP_ 896 EPAS_SystemStatus 1 : EPAS_HandsOnLevel EPAS_StcActive EPAS_StcFault EPAS_StcUnavailable EPAS_SteeringFault EPAS_SteeringMode EPAS_SteeringReduced EPAS_SystemStatus_Counter EPAS_SytemStatus_Checksum EPAS_TorsionBarTorque H_CAN_EPS_ToiUnavailable H_CAN_EPSS_ToiActive H_CAN_EPSS_ToiFlt;
SIG_GROUP_ 848 EPASP_Status 1 : EPAS_Ecu1EacSts EPAS_Ecu1PowerMode EPAS_Ecu1Role EPAS_Ecu1State EPAS_Ecu1Status_Checksum EPAS_Ecu1Status_Counter;
SIG_GROUP_ 258 ESP_AebFb 1 : ESP_AebActive ESP_AebAvailable ESP_AebFeedback_Checksum ESP_AebFeedback_Counter ESP_DbsActive ESP_DbsAvailable ESP_DecelFeedback ESP_PrefillActiveFeedback ESP_PrefillAvailable iB_BrakePedalApplied iB_BrakePedalApplied_Q;
SIG_GROUP_ 524 ESP_Brake_Pressure 1 : ESP_BrakeP_Checksum ESP_BrakeP_Message_Counter ESP_BrakePressure_LF ESP_BrakePressure_LF_Q ESP_BrakePressure_LR ESP_BrakePressure_LR_Q ESP_BrakePressure_RF ESP_BrakePressure_RF_Q ESP_BrakePressure_RR ESP_BrakePressure_RR_Q ESP_MasterCyl_Pressure ESP_MasterCyl_Pressure_Q;
SIG_GROUP_ 811 ESP_EpbStatus 1 : ESP_EpbAvailable ESP_EpbClampForce ESP_EpbFunctionLamp ESP_EpbMessageDisplayRequest ESP_EpbServiceMode ESP_EpbStatus ESP_EpbStatus_Checksum ESP_EpbStatus_Counter ESP_EpbWarningLamp;
SIG_GROUP_ 520 ESP_Status 1 : ESP_Abs_Active ESP_Abs_OffRoad_Mode ESP_BrakeLightActive ESP_BrakeLightActive_Q ESP_BrkTrq ESP_Dtc_Active ESP_Esp_Active ESP_FaultLamp_ABS ESP_FaultLamp_EBD ESP_FaultLamp_VDC ESP_Hba_Active ESP_Hhc_Active ESP_Hhc_Available ESP_Lfc_Active ESP_Lfc_Available ESP_Partial_Mode ESP_Status_Checksum ESP_Status_Counter ESP_Tsm_Active ESP_Vehicle_Speed ESP_Vehicle_Speed_Q;
SIG_GROUP_ 432 ESP_TorqueLimit_Front 1 : ESP_Torque_Front_Checksum ESP_Torque_Front_Counter ESP_Torque_Front_Max ESP_Torque_Front_MaxQ ESP_Torque_Front_Min ESP_Torque_Front_MinQ;
SIG_GROUP_ 448 ESP_TorqueLimit_Rear 1 : ESP_Torque_Rear_Checksum ESP_Torque_Rear_Counter ESP_Torque_Rear_Max ESP_Torque_Rear_MaxQ ESP_Torque_Rear_Min ESP_Torque_Rear_MinQ;
SIG_GROUP_ 523 ESP_Wheel_Pulse 1 : ESP_Wheel_Pulse_CRC ESP_Wheel_Pulse_Left_Front ESP_Wheel_Pulse_Left_Front_Q ESP_Wheel_Pulse_Left_Rear ESP_Wheel_Pulse_Left_Rear_Q ESP_Wheel_Pulse_Message_Counter ESP_Wheel_Pulse_Right_Front ESP_Wheel_Pulse_Right_Front_Q ESP_Wheel_Pulse_Right_Rear ESP_Wheel_Pulse_Right_Rear_Q;
SIG_GROUP_ 521 ESP_WSpeed_Front 1 : ESP_Wheel_Dir_Left_Front ESP_Wheel_Dir_Right_Front ESP_Wheel_Speed_Left_Front ESP_Wheel_Speed_Left_Front_Q ESP_Wheel_Speed_Right_Front ESP_Wheel_Speed_Right_Front_Q ESP_WSpeed_Front_CRC ESP_WSpeed_Front_Message_Counter;
SIG_GROUP_ 522 ESP_WSpeed_Rear 1 : ESP_Wheel_Dir_Left_Rear ESP_Wheel_Dir_Right_Rear ESP_Wheel_Speed_Left_Rear ESP_Wheel_Speed_Left_Rear_Q ESP_Wheel_Speed_Right_Rear ESP_Wheel_Speed_Right_Rear_Q ESP_WSpeed_Rear_CRC ESP_WSpeed_Rear_Message_Counter;
SIG_GROUP_ 910 iBESP1 1 : iBESP1_AliveCounter iBESP1_Checksum iBESP1_ExtReqPrio iBESP1_ExtReqStatus iBESP1_sOutputRodAct iBESP1_sOutputRodAct_Q iBESP1_sOutputRodDriver iBESP1_sOutputRodDriver_Q;
SIG_GROUP_ 911 iBESP2 1 : iBESP2_AliveCounter iBESP2_BrakePedalApplied iBESP2_BrakePedalApplied_Q iBESP2_Checksum iBESP2_CompatibilityIndex iBESP2_HbcRequest iBESP2_iBDiagActive iBESP2_pRunout iBESP2_pRunout_Q iBESP2_RprMode;
SIG_GROUP_ 1640 OCS_PassSeatInfo 1 : OCS_Checksum OCS_Counter OCS_FrontPassClass OCS_FrontPassClassValid OCS_FrontPassFaultStatus OCS_FrontPassSBRStatus OCS_OperatingMode OCS_Reserved_1 OCS_Reserved_2;
SIG_GROUP_ 516 RCM_ALR_Status 1 : RCM_ALR_Status_Signal;
SIG_GROUP_ 1280 RCM_Dtc 1 : RCM_Dtc_Checksum RCM_Dtc_Counter RCM_Dtc_HighByte RCM_Dtc_LowByte RCM_Dtc_MidByte RCM_Dtc_Number RCM_Dtc_Stat_Bit;
SIG_GROUP_ 309 RCM_IMU_HeaveRoll 1 : RCM_HeaveRoll_Checksum RCM_HeaveRoll_Counter RCM_IMU_Heave RCM_IMU_Heave_Stat_Fail RCM_IMU_Heave_Stat_Init RCM_IMU_Heave_Stat_SensAvail RCM_IMU_Heave_Stat_Startup RCM_IMU_Roll RCM_IMU_Roll_Stat_Fail RCM_IMU_Roll_Stat_Init RCM_IMU_Roll_Stat_SensAvail RCM_IMU_Roll_Stat_Startup;
SIG_GROUP_ 304 RCM_IMU_LatAccYaw 1 : RCM_IMU_LatAcc RCM_IMU_LatAcc_Stat_Fail RCM_IMU_LatAcc_Stat_Init RCM_IMU_LatAcc_Stat_SensAvail RCM_IMU_LatAcc_Stat_Startup RCM_IMU_Yaw RCM_IMU_Yaw_Stat_Fail RCM_IMU_Yaw_Stat_Init RCM_IMU_Yaw_Stat_SensAvail RCM_IMU_Yaw_Stat_Startup RCM_LateralAccelYaw_Checksum RCM_LateralAccelYaw_Counter;
SIG_GROUP_ 320 RCM_IMU_LongAcc 1 : RCM_IMU_LongAcc_Sig RCM_IMU_LongAcc_Stat_Fail RCM_IMU_LongAcc_Stat_Init RCM_IMU_LongAcc_Stat_SensAvail RCM_IMU_LongAcc_Stat_Startup RCM_LongAcc_Checksum RCM_LongAcc_Counter;
SIG_GROUP_ 1281 RCM_SerialIdentifier 1 : RCM_SerialNumber;
SIG_GROUP_ 826 RCM_Status 1 : RCM_IMU_LongAcc_Checksum RCM_IMU_LongAcc_MSG_Counter RCM_Status_DETECT_CRUSH RCM_Status_IND_ACT_RCM_PASS RCM_Status_IND_WARN_BELT_DRIVER RCM_Status_IND_WARN_BELT_PASS RCM_Status_IND_WARN_RCM;
SIG_GROUP_ 64 SAS_Status 1 : SAS_Status_AngleSafe SAS_Status_AngleSpeedSafe SAS_Status_Calibrated SAS_Status_Checksum SAS_Status_Counter SAS_StatusQ;
SIG_GROUP_ 357 VDM_AdasStalk 1 : VDM_AdasStalk_Checksum VDM_AdasStalk_Counter VDM_AdasStalkAccCancelRes VDM_AdasStalkAccEnableAdj VDM_AdasStalkAutonomyButton VDM_AdasStalkGapAdjust;
SIG_GROUP_ 354 VDM_AdasSts 1 : VDM_AdasAccelLimit VDM_AdasAccelRequest VDM_AdasAccelRequestAcknowledged VDM_AdasDecelLimit VDM_AdasDriverAccelPriorityStatu VDM_AdasDriverModeStatus VDM_AdasFaultStatus VDM_AdasInterfaceStatus VDM_AdasStatus_Checksum VDM_AdasStatus_Counter VDM_AdasVehicleHoldStatus;
SIG_GROUP_ 384 VDM_CGM_GW 1 : CGM_DriverPresent CGM_IgnSwtState CGM_TimeSinceLastIgnitionOn CGM_TrailerPresent VDM_CGM_GW_Checksum VDM_CGM_GW_Counter;
SIG_GROUP_ 592 VDM_EcasStatus 1 : VDM_EcasHeightFL VDM_EcasHeightFR VDM_EcasHeightRL VDM_EcasHeightRR;
SIG_GROUP_ 929 VDM_ModSw_DrvModPosSts_GW 1 : VDM_AchDriveMode VDM_AchDriveMode4x4 VDM_AchDriveModeAbs VDM_AchDriveModeAirSuspension VDM_AchDriveModeDamping VDM_AchDriveModeDrivability VDM_AchDriveModeEpas VDM_AchDriveModeEsp VDM_AchDriveModeRequestConfirm VDM_AchDriveModeRequestPullRearw VDM_AchDriveModeRequestPushDown VDM_AchDriveModeRequestPushForwa VDM_AchDriveModeRequestPushUp VDM_AchDriveModeRequestRest VDM_AchDriveModeRollControl VDM_AchDriveModeTcs;
SIG_GROUP_ 338 VDM_OutputSignals 1 : VDM_ABSOffRoadModeRequest VDM_BrakeLightRequest VDM_EpasPowerMode VDM_EpbRequest VDM_EspPartialModeRequest VDM_HhcActiveRequest VDM_Lfc_BrakeTorqueRequest VDM_LfcActiveRequest VDM_LfcRequestType VDM_OutputSigs_Checksum VDM_OutputSigs_Counter VDM_StcActiveRequest VDM_StcFault VDM_StcTorqueRequest VDM_SteeringModeRequest;
SIG_GROUP_ 336 VDM_PropStatus 1 : VDM_AcceleratorPedalPosition VDM_Prndl_Request VDM_Prndl_Status VDM_PropsnActv VDM_PropStatus_Checksum VDM_PropStatus_Counter VDM_VehicleSpeed VDM_VehicleSpeedQ;
SIG_GROUP_ 529 VDM_Torque_Front 1 : VDM_DriverIntendedTorqueFront VDM_OutputTorqueFront VDM_OutputTorqueFrontQ VDM_Torque_Front_Checksum VDM_Torque_Front_Counter VDM_Torque_Front_Max VDM_Torque_Front_MaxQ VDM_Torque_Front_Min VDM_Torque_Front_MinQ;
SIG_GROUP_ 530 VDM_Torque_Rear 1 : VDM_DriverIntendedTorque_Rear VDM_OutputTorqueRear VDM_OutputTorqueRearQ VDM_Torque_Rear_Checksum VDM_Torque_Rear_Counter VDM_Torque_Rear_Max VDM_Torque_Rear_MaxQ VDM_Torque_Rear_Min VDM_Torque_Rear_MinQ;
